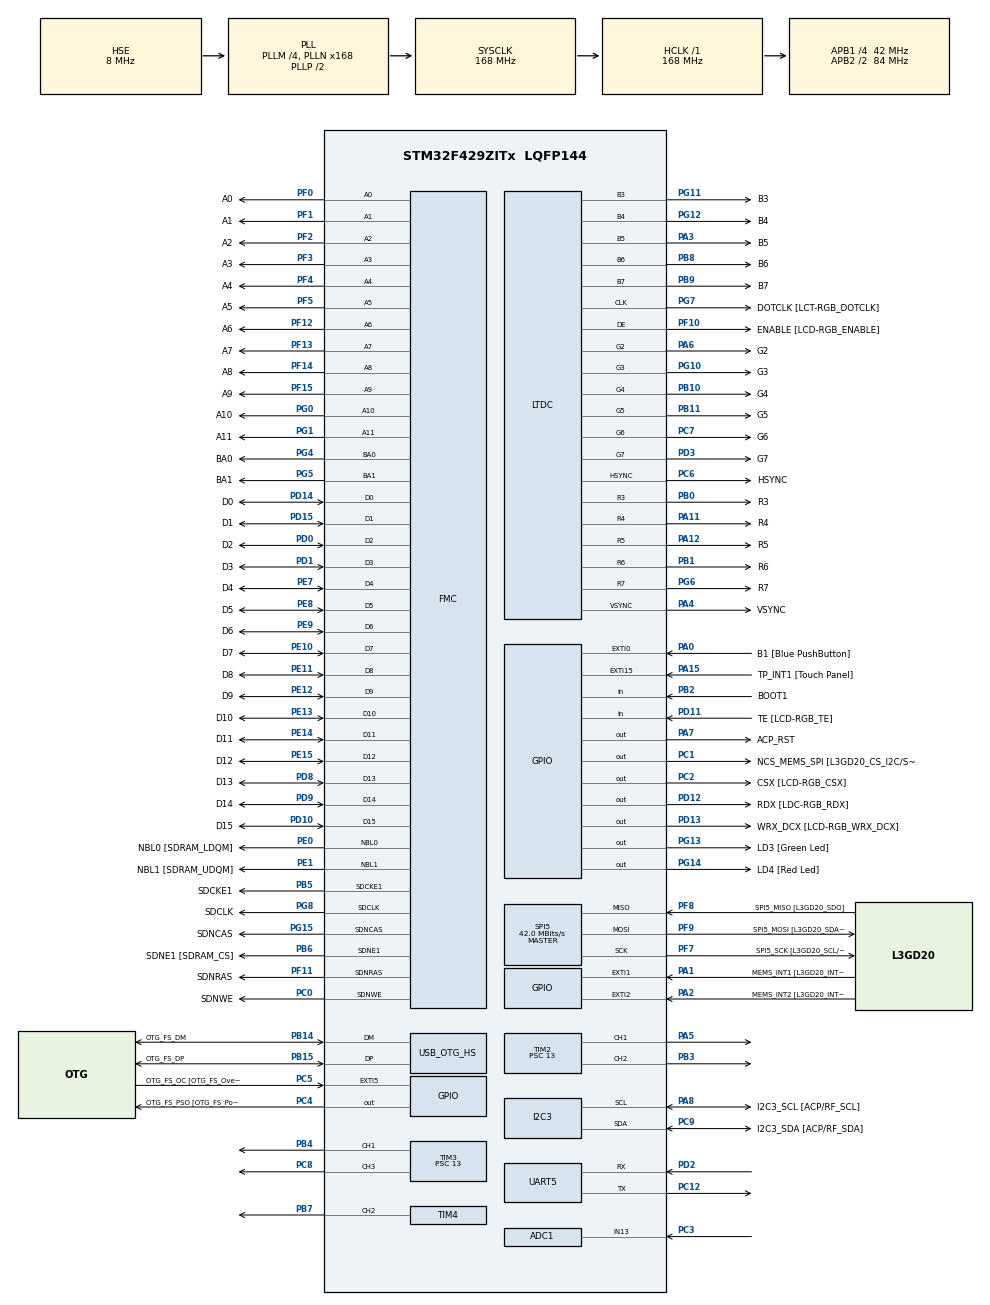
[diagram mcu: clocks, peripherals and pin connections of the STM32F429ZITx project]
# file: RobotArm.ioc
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ADC1.Channel-0\#ChannelRegularConversion=ADC_CHANNEL_13
ADC1.Channel-1\#ChannelRegularConversion=ADC_CHANNEL_TEMPSENSOR
ADC1.Channel-2\#ChannelRegularConversion=ADC_CHANNEL_VREFINT
ADC1.ClockPrescaler=ADC_CLOCK_SYNC_PCLK_DIV4
ADC1.ContinuousConvMode=ENABLE
ADC1.DMAContinuousRequests=ENABLE
ADC1.DataAlign=ADC_DATAALIGN_RIGHT
ADC1.DiscontinuousConvMode=DISABLE
ADC1.EOCSelection=ADC_EOC_SINGLE_CONV
ADC1.EnableAnalogWatchDog=false
ADC1.ExternalTrigConv=ADC_SOFTWARE_START
ADC1.ExternalTrigConvEdge=ADC_EXTERNALTRIGCONVEDGE_NONE
ADC1.InjNumberOfConversion=0
ADC1.NbrOfConversion=3
ADC1.NbrOfConversionFlag=1
ADC1.Rank-0\#ChannelRegularConversion=1
ADC1.Rank-1\#ChannelRegularConversion=2
ADC1.Rank-2\#ChannelRegularConversion=3
ADC1.Resolution=ADC_RESOLUTION_12B
ADC1.SamplingTime-0\#ChannelRegularConversion=ADC_SAMPLETIME_15CYCLES
ADC1.SamplingTime-1\#ChannelRegularConversion=ADC_SAMPLETIME_15CYCLES
ADC1.SamplingTime-2\#ChannelRegularConversion=ADC_SAMPLETIME_15CYCLES
ADC1.ScanConvMode=ENABLE
ADC1.master=1
DMA2D.AlphaModeForeground=DMA2D_NO_MODIF_ALPHA
DMA2D.ColorMode=DMA2D_OUTPUT_ARGB8888
DMA2D.InputAlphaForeground=0xFF
DMA2D.Mode=DMA2D_M2M
Dma.ADC1.0.Direction=DMA_PERIPH_TO_MEMORY
Dma.ADC1.0.FIFOMode=DMA_FIFOMODE_DISABLE
Dma.ADC1.0.Instance=DMA2_Stream4
Dma.ADC1.0.MemDataAlignment=DMA_MDATAALIGN_WORD
Dma.ADC1.0.MemInc=DMA_MINC_ENABLE
Dma.ADC1.0.Mode=DMA_CIRCULAR
Dma.ADC1.0.PeriphDataAlignment=DMA_PDATAALIGN_WORD
Dma.ADC1.0.PeriphInc=DMA_PINC_DISABLE
Dma.ADC1.0.Priority=DMA_PRIORITY_LOW
Dma.Request0=ADC1
FMC.CASLatency1=FMC_SDRAM_CAS_LATENCY_3
FMC.ExitSelfRefreshDelay1=7
FMC.LoadToActiveDelay1=2
FMC.RCDDelay1=2
FMC.RPDelay1=2
FMC.RPDelay2=2
FMC.ReadPipeDelay1=FMC_SDRAM_RPIPE_DELAY_1
FMC.ReadPipeDelay2=FMC_SDRAM_RPIPE_DELAY_1
FMC.RowCycleDelay1=7
FMC.RowCycleDelay2=7
FMC.SDClockPeriod1=FMC_SDRAM_CLOCK_PERIOD_2
FMC.SDClockPeriod2=FMC_SDRAM_CLOCK_PERIOD_2
FMC.SelfRefreshTime1=4
FMC.WriteRecoveryTime1=3
FREERTOS.Tasks01=defaultTask,-2,256,StartDefaultTask,Default,NULL,Dynamic,NULL,NULL;commTask,2,128,StartCommTask,Default,NULL,Dynamic,NULL,NULL;sensorTask,-1,128,StartSensorTask,Default,NULL,Dynamic,NULL,NULL;controlTask,1,128,StartControlTask,Default,NULL,Dynamic,NULL,NULL;servoRampTask,0,128,StartServoRampTask,Default,NULL,Dynamic,NULL,NULL;tsTask,0,128,StartTsTask,Default,NULL,Dynamic,NULL,NULL;oldGraphicsTask,-2,256,StartOldGraphicsTask,Default,NULL,Dynamic,NULL,NULL
GRAPHICS.Check_OTM8009A_PixelFormat-STemWin_F429_439=1
GRAPHICS.DMA2D_Graphics-STemWin_F429_439=1
GRAPHICS.EA_1_executable_name-STemWin_F429_439=GUIBuilder.exe
GRAPHICS.GUI_NUM_LAYERS-STemWin_F429_439=1
GRAPHICS.GUI_Num_KBYTES=110
GRAPHICS.GUI_Optimization=0
GRAPHICS.LIN_Frame_Buffer_Depth_Layer0-STemWin_F429_439=32
GRAPHICS.OPTIM_OS_use-STemWin_F429_439=6
GRAPHICS.USE_Embedded_Wizard-STemWin_F429_439=0
GRAPHICS.USE_STTouchGFX-STemWin_F429_439=0
GRAPHICS.UseGUIBuilder=Enabled
GRAPHICS.Use_SDRAM-STemWin_F429_439=SDRAM1_BANK2
GRAPHICS.Use_ili9341_Check-STemWin_F429_439=1
LTDC.ActiveH=320
LTDC.ActiveW=240
LTDC.Alpha_L0=255
LTDC.Alpha_L1=255
LTDC.BlendingFactor1_L0=LTDC_BLENDING_FACTOR1_PAxCA
LTDC.BlendingFactor1_L1=LTDC_BLENDING_FACTOR1_PAxCA
LTDC.BlendingFactor2_L0=LTDC_BLENDING_FACTOR2_PAxCA
LTDC.BlendingFactor2_L1=LTDC_BLENDING_FACTOR2_PAxCA
LTDC.FBStartAdress_L0=0xD0200000
LTDC.FBStartAdress_L1=0xD0400000
LTDC.HBP=20
LTDC.HFP=10
LTDC.HSync=10
LTDC.ImageHeight_L0=320
LTDC.ImageHeight_L1=320
LTDC.ImageWidth_L0=240
LTDC.ImageWidth_L1=240
LTDC.Layers=0
LTDC.PixelFormat_L0=LTDC_PIXEL_FORMAT_ARGB8888
LTDC.PixelFormat_L1=LTDC_PIXEL_FORMAT_ARGB8888
LTDC.VBP=2
LTDC.VFP=4
LTDC.VSync=2
LTDC.WindowX1_L0=240
LTDC.WindowX1_L1=240
LTDC.WindowY1_L0=320
LTDC.WindowY1_L1=320
Mcu.Family=STM32F4
Mcu.Name=STM32F429ZITx
Mcu.Package=LQFP144
NVIC.DMA2D_IRQn=true\:5\:0\:false\:false\:true\:true\:true
NVIC.DMA2_Stream4_IRQn=true\:0\:0\:false\:false\:true\:false\:false
NVIC.OTG_HS_IRQn=true\:5\:0\:false\:false\:true\:true\:false
NVIC.PriorityGroup=NVIC_PRIORITYGROUP_4
NVIC.TIM6_DAC_IRQn=true\:0\:0\:false\:false\:true\:false\:true
NVIC.TimeBase=TIM6_DAC_IRQn
NVIC.TimeBaseIP=TIM6
PA0/WKUP.GPIO_Label=B1 [Blue PushButton]
PA0/WKUP.GPIO_ModeDefaultEXTI=GPIO_MODE_EVT_RISING
PA0/WKUP.GPIO_PuPd=GPIO_NOPULL
PA0/WKUP.Signal=GPXTI0
PA1.GPIO_Label=MEMS_INT1 [L3GD20_INT1]
PA1.GPIO_ModeDefaultEXTI=GPIO_MODE_EVT_RISING
PA1.GPIO_PuPd=GPIO_NOPULL
PA1.Signal=GPXTI1
PA11.GPIO_Label=R4
PA11.GPIO_Mode=GPIO_MODE_AF_PP
PA11.GPIO_PuPd=GPIO_NOPULL
PA11.GPIO_Speed=GPIO_SPEED_FREQ_LOW
PA11.Mode=RGB565
PA11.Signal=LTDC_R4
PA12.GPIO_Label=R5
PA12.GPIO_Mode=GPIO_MODE_AF_PP
PA12.GPIO_PuPd=GPIO_NOPULL
PA12.GPIO_Speed=GPIO_SPEED_FREQ_LOW
PA12.Mode=RGB565
PA12.Signal=LTDC_R5
PA13.GPIO_Label=SWDIO
PA13.Signal=SYS_JTMS-SWDIO
PA14.GPIO_Label=SWCLK
PA14.Signal=SYS_JTCK-SWCLK
PA15.GPIO_Label=TP_INT1 [Touch Panel]
PA15.GPIO_ModeDefaultEXTI=GPIO_MODE_EVT_RISING
PA15.GPIO_PuPd=GPIO_NOPULL
PA15.Signal=GPXTI15
PA2.GPIO_Label=MEMS_INT2 [L3GD20_INT2]
PA2.GPIO_ModeDefaultEXTI=GPIO_MODE_EVT_RISING
PA2.GPIO_PuPd=GPIO_NOPULL
PA2.Signal=GPXTI2
PA3.GPIO_Label=B5
PA3.GPIO_Mode=GPIO_MODE_AF_PP
PA3.GPIO_PuPd=GPIO_NOPULL
PA3.GPIO_Speed=GPIO_SPEED_FREQ_LOW
PA3.Mode=RGB565
PA3.Signal=LTDC_B5
PA4.GPIO_Label=VSYNC
PA4.GPIO_Mode=GPIO_MODE_AF_PP
PA4.GPIO_PuPd=GPIO_NOPULL
PA4.GPIO_Speed=GPIO_SPEED_FREQ_LOW
PA4.Mode=RGB565
PA4.Signal=LTDC_VSYNC
PA5.Signal=S_TIM2_CH1_ETR
PA6.GPIO_Label=G2
PA6.GPIO_Mode=GPIO_MODE_AF_PP
PA6.GPIO_PuPd=GPIO_NOPULL
PA6.GPIO_Speed=GPIO_SPEED_FREQ_LOW
PA6.Mode=RGB565
PA6.Signal=LTDC_G2
PA7.GPIO_Label=ACP_RST
PA7.GPIO_Mode=GPIO_MODE_OUTPUT_PP
PA7.GPIO_PuPd=GPIO_NOPULL
PA7.GPIO_Speed=GPIO_SPEED_FREQ_LOW
PA7.Signal=GPIO_Output
PA8.GPIO_Label=I2C3_SCL [ACP/RF_SCL]
PA8.GPIO_Mode=GPIO_MODE_AF_OD
PA8.GPIO_PuPd=GPIO_NOPULL
PA8.GPIO_Speed=GPIO_SPEED_FREQ_LOW
PA8.Mode=I2C
PA8.Signal=I2C3_SCL
PB0.GPIO_Label=R3
PB0.GPIO_Mode=GPIO_MODE_AF_PP
PB0.GPIO_PuPd=GPIO_NOPULL
PB0.GPIO_Speed=GPIO_SPEED_FREQ_LOW
PB0.Mode=RGB565
PB0.Signal=LTDC_R3
PB1.GPIO_Label=R6
PB1.GPIO_Mode=GPIO_MODE_AF_PP
PB1.GPIO_PuPd=GPIO_NOPULL
PB1.GPIO_Speed=GPIO_SPEED_FREQ_LOW
PB1.Mode=RGB565
PB1.Signal=LTDC_R6
PB10.GPIO_Label=G4
PB10.GPIO_Mode=GPIO_MODE_AF_PP
PB10.GPIO_PuPd=GPIO_NOPULL
PB10.GPIO_Speed=GPIO_SPEED_FREQ_LOW
PB10.Mode=RGB565
PB10.Signal=LTDC_G4
PB11.GPIO_Label=G5
PB11.GPIO_Mode=GPIO_MODE_AF_PP
PB11.GPIO_PuPd=GPIO_NOPULL
PB11.GPIO_Speed=GPIO_SPEED_FREQ_LOW
PB11.Mode=RGB565
PB11.Signal=LTDC_G5
PB12.GPIO_Label=OTG_FS_ID
PB12.GPIO_Mode=GPIO_MODE_AF_PP
PB12.GPIO_PuPd=GPIO_NOPULL
PB12.GPIO_Speed=GPIO_SPEED_FREQ_LOW
PB12.Signal=USB_OTG_HS_ID
PB13.GPIO_Label=VBUS_FS
PB13.GPIO_Mode=GPIO_MODE_INPUT
PB13.GPIO_PuPd=GPIO_NOPULL
PB13.Signal=USB_OTG_HS_VBUS
PB14.GPIO_Label=OTG_FS_DM
PB14.GPIO_Mode=GPIO_MODE_AF_PP
PB14.GPIO_PuPd=GPIO_NOPULL
PB14.GPIO_Speed=GPIO_SPEED_FREQ_LOW
PB14.Mode=Device_Only_FS
PB14.Signal=USB_OTG_HS_DM
PB15.GPIO_Label=OTG_FS_DP
PB15.GPIO_Mode=GPIO_MODE_AF_PP
PB15.GPIO_PuPd=GPIO_NOPULL
PB15.GPIO_Speed=GPIO_SPEED_FREQ_LOW
PB15.Mode=Device_Only_FS
PB15.Signal=USB_OTG_HS_DP
PB2/BOOT1.GPIO_Label=BOOT1
PB2/BOOT1.GPIO_Mode=GPIO_MODE_INPUT
PB2/BOOT1.GPIO_PuPd=GPIO_NOPULL
PB2/BOOT1.Signal=GPIO_Input
PB3.Signal=S_TIM2_CH2
PB4.Signal=S_TIM3_CH1
PB5.GPIO_Label=SDCKE1
PB5.GPIO_Mode=GPIO_MODE_AF_PP
PB5.GPIO_PuPd=GPIO_NOPULL
PB5.GPIO_Speed=GPIO_SPEED_FREQ_VERY_HIGH
PB5.Mode=SdramChipSelect2_1
PB5.Signal=FMC_SDCKE1
PB6.GPIO_Label=SDNE1 [SDRAM_CS]
PB6.GPIO_Mode=GPIO_MODE_AF_PP
PB6.GPIO_PuPd=GPIO_NOPULL
PB6.GPIO_Speed=GPIO_SPEED_FREQ_VERY_HIGH
PB6.Mode=SdramChipSelect2_1
PB6.Signal=FMC_SDNE1
PB7.Signal=S_TIM4_CH2
PB8.GPIO_Label=B6
PB8.GPIO_Mode=GPIO_MODE_AF_PP
PB8.GPIO_PuPd=GPIO_NOPULL
PB8.GPIO_Speed=GPIO_SPEED_FREQ_LOW
PB8.Mode=RGB565
PB8.Signal=LTDC_B6
PB9.GPIO_Label=B7
PB9.GPIO_Mode=GPIO_MODE_AF_PP
PB9.GPIO_PuPd=GPIO_NOPULL
PB9.GPIO_Speed=GPIO_SPEED_FREQ_LOW
PB9.Mode=RGB565
PB9.Signal=LTDC_B7
PC0.GPIO_Label=SDNWE
PC0.GPIO_Mode=GPIO_MODE_AF_PP
PC0.GPIO_PuPd=GPIO_NOPULL
PC0.GPIO_Speed=GPIO_SPEED_FREQ_VERY_HIGH
PC0.Signal=FMC_SDNWE
PC1.GPIO_Label=NCS_MEMS_SPI [L3GD20_CS_I2C/SPI]
PC1.GPIO_Mode=GPIO_MODE_OUTPUT_PP
PC1.GPIO_PuPd=GPIO_NOPULL
PC1.GPIO_Speed=GPIO_SPEED_FREQ_LOW
PC1.Signal=GPIO_Output
PC10.GPIO_Label=R2
PC10.GPIO_Mode=GPIO_MODE_AF_PP
PC10.GPIO_PuPd=GPIO_NOPULL
PC10.GPIO_Speed=GPIO_SPEED_FREQ_LOW
PC10.Signal=LTDC_R2
PC12.Mode=Asynchronous
PC12.Signal=UART5_TX
PC14/OSC32_IN.GPIO_Label=PC14-OSC32_IN
PC14/OSC32_IN.Signal=RCC_OSC32_IN
PC15/OSC32_OUT.GPIO_Label=PC15-OSC32_OUT
PC15/OSC32_OUT.Signal=RCC_OSC32_OUT
PC2.GPIO_Label=CSX [LCD-RGB_CSX]
PC2.GPIO_Mode=GPIO_MODE_OUTPUT_PP
PC2.GPIO_PuPd=GPIO_NOPULL
PC2.GPIO_Speed=GPIO_SPEED_FREQ_LOW
PC2.Signal=GPIO_Output
PC3.Signal=ADCx_IN13
PC4.GPIO_Label=OTG_FS_PSO [OTG_FS_PowerSwitchOn]
PC4.GPIO_Mode=GPIO_MODE_OUTPUT_PP
PC4.GPIO_PuPd=GPIO_NOPULL
PC4.GPIO_Speed=GPIO_SPEED_FREQ_LOW
PC4.Signal=GPIO_Output
PC5.GPIO_Label=OTG_FS_OC [OTG_FS_OverCurrent]
PC5.GPIO_ModeDefaultEXTI=GPIO_MODE_EVT_RISING
PC5.Signal=GPXTI5
PC6.GPIO_Label=HSYNC
PC6.GPIO_Mode=GPIO_MODE_AF_PP
PC6.GPIO_PuPd=GPIO_NOPULL
PC6.GPIO_Speed=GPIO_SPEED_FREQ_LOW
PC6.Mode=RGB565
PC6.Signal=LTDC_HSYNC
PC7.GPIO_Label=G6
PC7.GPIO_Mode=GPIO_MODE_AF_PP
PC7.GPIO_PuPd=GPIO_NOPULL
PC7.GPIO_Speed=GPIO_SPEED_FREQ_LOW
PC7.Mode=RGB565
PC7.Signal=LTDC_G6
PC8.Signal=S_TIM3_CH3
PC9.GPIO_Label=I2C3_SDA [ACP/RF_SDA]
PC9.GPIO_Mode=GPIO_MODE_AF_OD
PC9.GPIO_PuPd=GPIO_NOPULL
PC9.GPIO_Speed=GPIO_SPEED_FREQ_LOW
PC9.Mode=I2C
PC9.Signal=I2C3_SDA
PD0.GPIO_Label=D2
PD0.GPIO_Mode=GPIO_MODE_AF_PP
PD0.GPIO_PuPd=GPIO_NOPULL
PD0.GPIO_Speed=GPIO_SPEED_FREQ_VERY_HIGH
PD0.Signal=FMC_D2_DA2
PD1.GPIO_Label=D3
PD1.GPIO_Mode=GPIO_MODE_AF_PP
PD1.GPIO_PuPd=GPIO_NOPULL
PD1.GPIO_Speed=GPIO_SPEED_FREQ_VERY_HIGH
PD1.Signal=FMC_D3_DA3
PD10.GPIO_Label=D15
PD10.GPIO_Mode=GPIO_MODE_AF_PP
PD10.GPIO_PuPd=GPIO_NOPULL
PD10.GPIO_Speed=GPIO_SPEED_FREQ_VERY_HIGH
PD10.Signal=FMC_D15_DA15
PD11.GPIO_Label=TE [LCD-RGB_TE]
PD11.GPIO_Mode=GPIO_MODE_INPUT
PD11.GPIO_PuPd=GPIO_NOPULL
PD11.Signal=GPIO_Input
PD12.GPIO_Label=RDX [LDC-RGB_RDX]
PD12.GPIO_Mode=GPIO_MODE_OUTPUT_PP
PD12.GPIO_PuPd=GPIO_NOPULL
PD12.GPIO_Speed=GPIO_SPEED_FREQ_LOW
PD12.Signal=GPIO_Output
PD13.GPIO_Label=WRX_DCX [LCD-RGB_WRX_DCX]
PD13.GPIO_Mode=GPIO_MODE_OUTPUT_PP
PD13.GPIO_PuPd=GPIO_NOPULL
PD13.GPIO_Speed=GPIO_SPEED_FREQ_LOW
PD13.Signal=GPIO_Output
PD14.GPIO_Label=D0
PD14.GPIO_Mode=GPIO_MODE_AF_PP
PD14.GPIO_PuPd=GPIO_NOPULL
PD14.GPIO_Speed=GPIO_SPEED_FREQ_VERY_HIGH
PD14.Signal=FMC_D0_DA0
PD15.GPIO_Label=D1
PD15.GPIO_Mode=GPIO_MODE_AF_PP
PD15.GPIO_PuPd=GPIO_NOPULL
PD15.GPIO_Speed=GPIO_SPEED_FREQ_VERY_HIGH
PD15.Signal=FMC_D1_DA1
PD2.Mode=Asynchronous
PD2.Signal=UART5_RX
PD3.GPIO_Label=G7
PD3.GPIO_Mode=GPIO_MODE_AF_PP
PD3.GPIO_PuPd=GPIO_NOPULL
PD3.GPIO_Speed=GPIO_SPEED_FREQ_LOW
PD3.Mode=RGB565
PD3.Signal=LTDC_G7
PD6.GPIO_Label=B2
PD6.GPIO_Mode=GPIO_MODE_AF_PP
PD6.GPIO_PuPd=GPIO_NOPULL
PD6.GPIO_Speed=GPIO_SPEED_FREQ_LOW
PD6.Signal=LTDC_B2
PD8.GPIO_Label=D13
PD8.GPIO_Mode=GPIO_MODE_AF_PP
PD8.GPIO_PuPd=GPIO_NOPULL
PD8.GPIO_Speed=GPIO_SPEED_FREQ_VERY_HIGH
PD8.Signal=FMC_D13_DA13
PD9.GPIO_Label=D14
PD9.GPIO_Mode=GPIO_MODE_AF_PP
PD9.GPIO_PuPd=GPIO_NOPULL
PD9.GPIO_Speed=GPIO_SPEED_FREQ_VERY_HIGH
PD9.Signal=FMC_D14_DA14
PE0.GPIO_Label=NBL0 [SDRAM_LDQM]
PE0.GPIO_Mode=GPIO_MODE_AF_PP
PE0.GPIO_PuPd=GPIO_NOPULL
PE0.GPIO_Speed=GPIO_SPEED_FREQ_VERY_HIGH
PE0.Signal=FMC_NBL0
PE1.GPIO_Label=NBL1 [SDRAM_UDQM]
PE1.GPIO_Mode=GPIO_MODE_AF_PP
PE1.GPIO_PuPd=GPIO_NOPULL
PE1.GPIO_Speed=GPIO_SPEED_FREQ_VERY_HIGH
PE1.Signal=FMC_NBL1
PE10.GPIO_Label=D7
PE10.GPIO_Mode=GPIO_MODE_AF_PP
PE10.GPIO_PuPd=GPIO_NOPULL
PE10.GPIO_Speed=GPIO_SPEED_FREQ_VERY_HIGH
PE10.Signal=FMC_D7_DA7
PE11.GPIO_Label=D8
PE11.GPIO_Mode=GPIO_MODE_AF_PP
PE11.GPIO_PuPd=GPIO_NOPULL
PE11.GPIO_Speed=GPIO_SPEED_FREQ_VERY_HIGH
PE11.Signal=FMC_D8_DA8
PE12.GPIO_Label=D9
PE12.GPIO_Mode=GPIO_MODE_AF_PP
PE12.GPIO_PuPd=GPIO_NOPULL
PE12.GPIO_Speed=GPIO_SPEED_FREQ_VERY_HIGH
PE12.Signal=FMC_D9_DA9
PE13.GPIO_Label=D10
PE13.GPIO_Mode=GPIO_MODE_AF_PP
PE13.GPIO_PuPd=GPIO_NOPULL
PE13.GPIO_Speed=GPIO_SPEED_FREQ_VERY_HIGH
PE13.Signal=FMC_D10_DA10
PE14.GPIO_Label=D11
PE14.GPIO_Mode=GPIO_MODE_AF_PP
PE14.GPIO_PuPd=GPIO_NOPULL
PE14.GPIO_Speed=GPIO_SPEED_FREQ_VERY_HIGH
PE14.Signal=FMC_D11_DA11
PE15.GPIO_Label=D12
PE15.GPIO_Mode=GPIO_MODE_AF_PP
PE15.GPIO_PuPd=GPIO_NOPULL
PE15.GPIO_Speed=GPIO_SPEED_FREQ_VERY_HIGH
PE15.Signal=FMC_D12_DA12
PE7.GPIO_Label=D4
PE7.GPIO_Mode=GPIO_MODE_AF_PP
PE7.GPIO_PuPd=GPIO_NOPULL
PE7.GPIO_Speed=GPIO_SPEED_FREQ_VERY_HIGH
PE7.Signal=FMC_D4_DA4
PE8.GPIO_Label=D5
PE8.GPIO_Mode=GPIO_MODE_AF_PP
PE8.GPIO_PuPd=GPIO_NOPULL
PE8.GPIO_Speed=GPIO_SPEED_FREQ_VERY_HIGH
PE8.Signal=FMC_D5_DA5
PE9.GPIO_Label=D6
PE9.GPIO_Mode=GPIO_MODE_AF_PP
PE9.GPIO_PuPd=GPIO_NOPULL
PE9.GPIO_Speed=GPIO_SPEED_FREQ_VERY_HIGH
PE9.Signal=FMC_D6_DA6
PF0.GPIO_Label=A0
PF0.GPIO_Mode=GPIO_MODE_AF_PP
PF0.GPIO_PuPd=GPIO_NOPULL
PF0.GPIO_Speed=GPIO_SPEED_FREQ_VERY_HIGH
PF0.Signal=FMC_A0
PF1.GPIO_Label=A1
PF1.GPIO_Mode=GPIO_MODE_AF_PP
PF1.GPIO_PuPd=GPIO_NOPULL
PF1.GPIO_Speed=GPIO_SPEED_FREQ_VERY_HIGH
PF1.Signal=FMC_A1
PF10.GPIO_Label=ENABLE [LCD-RGB_ENABLE]
PF10.GPIO_Mode=GPIO_MODE_AF_PP
PF10.GPIO_PuPd=GPIO_NOPULL
PF10.GPIO_Speed=GPIO_SPEED_FREQ_LOW
PF10.Mode=RGB565
PF10.Signal=LTDC_DE
PF11.GPIO_Label=SDNRAS
PF11.GPIO_Mode=GPIO_MODE_AF_PP
PF11.GPIO_PuPd=GPIO_NOPULL
PF11.GPIO_Speed=GPIO_SPEED_FREQ_VERY_HIGH
PF11.Signal=FMC_SDNRAS
PF12.GPIO_Label=A6
PF12.GPIO_Mode=GPIO_MODE_AF_PP
PF12.GPIO_PuPd=GPIO_NOPULL
PF12.GPIO_Speed=GPIO_SPEED_FREQ_VERY_HIGH
PF12.Signal=FMC_A6
PF13.GPIO_Label=A7
PF13.GPIO_Mode=GPIO_MODE_AF_PP
PF13.GPIO_PuPd=GPIO_NOPULL
PF13.GPIO_Speed=GPIO_SPEED_FREQ_VERY_HIGH
PF13.Signal=FMC_A7
PF14.GPIO_Label=A8
PF14.GPIO_Mode=GPIO_MODE_AF_PP
PF14.GPIO_PuPd=GPIO_NOPULL
PF14.GPIO_Speed=GPIO_SPEED_FREQ_VERY_HIGH
PF14.Signal=FMC_A8
PF15.GPIO_Label=A9
PF15.GPIO_Mode=GPIO_MODE_AF_PP
PF15.GPIO_PuPd=GPIO_NOPULL
PF15.GPIO_Speed=GPIO_SPEED_FREQ_VERY_HIGH
PF15.Signal=FMC_A9
PF2.GPIO_Label=A2
PF2.GPIO_Mode=GPIO_MODE_AF_PP
PF2.GPIO_PuPd=GPIO_NOPULL
PF2.GPIO_Speed=GPIO_SPEED_FREQ_VERY_HIGH
PF2.Signal=FMC_A2
PF3.GPIO_Label=A3
PF3.GPIO_Mode=GPIO_MODE_AF_PP
PF3.GPIO_PuPd=GPIO_NOPULL
PF3.GPIO_Speed=GPIO_SPEED_FREQ_VERY_HIGH
PF3.Signal=FMC_A3
PF4.GPIO_Label=A4
PF4.GPIO_Mode=GPIO_MODE_AF_PP
PF4.GPIO_PuPd=GPIO_NOPULL
PF4.GPIO_Speed=GPIO_SPEED_FREQ_VERY_HIGH
PF4.Signal=FMC_A4
PF5.GPIO_Label=A5
PF5.GPIO_Mode=GPIO_MODE_AF_PP
PF5.GPIO_PuPd=GPIO_NOPULL
PF5.GPIO_Speed=GPIO_SPEED_FREQ_VERY_HIGH
PF5.Signal=FMC_A5
PF7.GPIO_Label=SPI5_SCK [L3GD20_SCL/SPC]
PF7.GPIO_Mode=GPIO_MODE_AF_PP
PF7.GPIO_PuPd=GPIO_NOPULL
PF7.GPIO_Speed=GPIO_SPEED_FREQ_LOW
PF7.Mode=Full_Duplex_Master
PF7.Signal=SPI5_SCK
PF8.GPIO_Label=SPI5_MISO [L3GD20_SDO]
PF8.GPIO_Mode=GPIO_MODE_AF_PP
PF8.GPIO_PuPd=GPIO_NOPULL
PF8.GPIO_Speed=GPIO_SPEED_FREQ_LOW
PF8.Mode=Full_Duplex_Master
PF8.Signal=SPI5_MISO
PF9.GPIO_Label=SPI5_MOSI [L3GD20_SDA/SDI/SDO]
PF9.GPIO_Mode=GPIO_MODE_AF_PP
PF9.GPIO_PuPd=GPIO_NOPULL
PF9.GPIO_Speed=GPIO_SPEED_FREQ_LOW
PF9.Mode=Full_Duplex_Master
PF9.Signal=SPI5_MOSI
PG0.GPIO_Label=A10
PG0.GPIO_Mode=GPIO_MODE_AF_PP
PG0.GPIO_PuPd=GPIO_NOPULL
PG0.GPIO_Speed=GPIO_SPEED_FREQ_VERY_HIGH
PG0.Signal=FMC_A10
PG1.GPIO_Label=A11
PG1.GPIO_Mode=GPIO_MODE_AF_PP
PG1.GPIO_PuPd=GPIO_NOPULL
PG1.GPIO_Speed=GPIO_SPEED_FREQ_VERY_HIGH
PG1.Signal=FMC_A11
PG10.GPIO_Label=G3
PG10.GPIO_Mode=GPIO_MODE_AF_PP
PG10.GPIO_PuPd=GPIO_NOPULL
PG10.GPIO_Speed=GPIO_SPEED_FREQ_LOW
PG10.Mode=RGB565
PG10.Signal=LTDC_G3
PG11.GPIO_Label=B3
PG11.GPIO_Mode=GPIO_MODE_AF_PP
PG11.GPIO_PuPd=GPIO_NOPULL
PG11.GPIO_Speed=GPIO_SPEED_FREQ_LOW
PG11.Mode=RGB565
PG11.Signal=LTDC_B3
PG12.GPIO_Label=B4
PG12.GPIO_Mode=GPIO_MODE_AF_PP
PG12.GPIO_PuPd=GPIO_NOPULL
PG12.GPIO_Speed=GPIO_SPEED_FREQ_LOW
PG12.Mode=RGB565
PG12.Signal=LTDC_B4
PG13.GPIO_Label=LD3 [Green Led]
PG13.GPIO_Mode=GPIO_MODE_OUTPUT_PP
PG13.GPIO_PuPd=GPIO_NOPULL
PG13.GPIO_Speed=GPIO_SPEED_FREQ_LOW
PG13.Signal=GPIO_Output
PG14.GPIO_Label=LD4 [Red Led]
PG14.GPIO_Mode=GPIO_MODE_OUTPUT_PP
PG14.GPIO_PuPd=GPIO_NOPULL
PG14.GPIO_Speed=GPIO_SPEED_FREQ_LOW
PG14.Signal=GPIO_Output
PG15.GPIO_Label=SDNCAS
PG15.GPIO_Mode=GPIO_MODE_AF_PP
PG15.GPIO_PuPd=GPIO_NOPULL
PG15.GPIO_Speed=GPIO_SPEED_FREQ_VERY_HIGH
PG15.Signal=FMC_SDNCAS
PG4.GPIO_Label=BA0
PG4.GPIO_Mode=GPIO_MODE_AF_PP
PG4.GPIO_PuPd=GPIO_NOPULL
PG4.GPIO_Speed=GPIO_SPEED_FREQ_VERY_HIGH
PG4.Signal=FMC_A14_BA0
PG5.GPIO_Label=BA1
PG5.GPIO_Mode=GPIO_MODE_AF_PP
PG5.GPIO_PuPd=GPIO_NOPULL
PG5.GPIO_Speed=GPIO_SPEED_FREQ_VERY_HIGH
PG5.Signal=FMC_A15_BA1
PG6.GPIO_Label=R7
PG6.GPIO_Mode=GPIO_MODE_AF_PP
PG6.GPIO_PuPd=GPIO_NOPULL
PG6.GPIO_Speed=GPIO_SPEED_FREQ_LOW
PG6.Mode=RGB565
PG6.Signal=LTDC_R7
PG7.GPIO_Label=DOTCLK [LCT-RGB_DOTCLK]
PG7.GPIO_Mode=GPIO_MODE_AF_PP
PG7.GPIO_PuPd=GPIO_NOPULL
PG7.GPIO_Speed=GPIO_SPEED_FREQ_LOW
PG7.Mode=RGB565
PG7.Signal=LTDC_CLK
PG8.GPIO_Label=SDCLK
PG8.GPIO_Mode=GPIO_MODE_AF_PP
PG8.GPIO_PuPd=GPIO_NOPULL
PG8.GPIO_Speed=GPIO_SPEED_FREQ_VERY_HIGH
PG8.Signal=FMC_SDCLK
PH0/OSC_IN.GPIO_Label=PH0-OSC_IN
PH0/OSC_IN.Mode=HSE-External-Oscillator
PH0/OSC_IN.Signal=RCC_OSC_IN
PH1/OSC_OUT.GPIO_Label=PH1-OSC_OUT
PH1/OSC_OUT.Mode=HSE-External-Oscillator
PH1/OSC_OUT.Signal=RCC_OSC_OUT
ProjectManager.HeapSize=0x1000
ProjectManager.StackSize=0x600
ProjectManager.TargetToolchain=EWARM
RCC.48MHZClocksFreq_Value=48000000
RCC.AHBFreq_Value=168000000
RCC.APB1CLKDivider=RCC_HCLK_DIV4
RCC.APB1Freq_Value=42000000
RCC.APB1TimFreq_Value=84000000
RCC.APB2CLKDivider=RCC_HCLK_DIV2
RCC.APB2Freq_Value=84000000
RCC.APB2TimFreq_Value=168000000
RCC.CortexFreq_Value=168000000
RCC.HCLKFreq_Value=168000000
RCC.HSE_VALUE=8000000
RCC.HSI_VALUE=16000000
RCC.LSE_VALUE=32768
RCC.PLLM=4
RCC.PLLN=168
RCC.PLLQ=7
RCC.PLLSAIDivR=RCC_PLLSAIDIVR_4
RCC.PLLSAIN=84
RCC.PLLSAIR=7
RCC.SYSCLKFreq_VALUE=168000000
RCC.SYSCLKSource=RCC_SYSCLKSOURCE_PLLCLK
RCC.VCOOutputFreq_Value=336000000
SH.ADCx_IN13.0=ADC1_IN13,IN13
SH.FMC_A0.0=FMC_A0,12b-sda1
SH.FMC_A1.0=FMC_A1,12b-sda1
SH.FMC_A10.0=FMC_A10,12b-sda1
SH.FMC_A11.0=FMC_A11,12b-sda1
SH.FMC_A14_BA0.0=FMC_BA0,FourSdramBanks1
SH.FMC_A15_BA1.0=FMC_BA1,FourSdramBanks1
SH.FMC_A2.0=FMC_A2,12b-sda1
SH.FMC_A3.0=FMC_A3,12b-sda1
SH.FMC_A4.0=FMC_A4,12b-sda1
SH.FMC_A5.0=FMC_A5,12b-sda1
SH.FMC_A6.0=FMC_A6,12b-sda1
SH.FMC_A7.0=FMC_A7,12b-sda1
SH.FMC_A8.0=FMC_A8,12b-sda1
SH.FMC_A9.0=FMC_A9,12b-sda1
SH.FMC_D0_DA0.0=FMC_D0,sd-16b-d1
SH.FMC_D10_DA10.0=FMC_D10,sd-16b-d1
SH.FMC_D11_DA11.0=FMC_D11,sd-16b-d1
SH.FMC_D12_DA12.0=FMC_D12,sd-16b-d1
SH.FMC_D13_DA13.0=FMC_D13,sd-16b-d1
SH.FMC_D14_DA14.0=FMC_D14,sd-16b-d1
SH.FMC_D15_DA15.0=FMC_D15,sd-16b-d1
SH.FMC_D1_DA1.0=FMC_D1,sd-16b-d1
SH.FMC_D2_DA2.0=FMC_D2,sd-16b-d1
SH.FMC_D3_DA3.0=FMC_D3,sd-16b-d1
SH.FMC_D4_DA4.0=FMC_D4,sd-16b-d1
SH.FMC_D5_DA5.0=FMC_D5,sd-16b-d1
SH.FMC_D6_DA6.0=FMC_D6,sd-16b-d1
SH.FMC_D7_DA7.0=FMC_D7,sd-16b-d1
SH.FMC_D8_DA8.0=FMC_D8,sd-16b-d1
SH.FMC_D9_DA9.0=FMC_D9,sd-16b-d1
SH.FMC_NBL0.0=FMC_NBL0,Sd2ByteEnable1
SH.FMC_NBL1.0=FMC_NBL1,Sd2ByteEnable1
SH.FMC_SDCLK.0=FMC_SDCLK,12b-sda1
SH.FMC_SDNCAS.0=FMC_SDNCAS,12b-sda1
SH.FMC_SDNRAS.0=FMC_SDNRAS,12b-sda1
SH.FMC_SDNWE.0=FMC_SDNWE,12b-sda1
SH.S_TIM2_CH1_ETR.0=TIM2_CH1,PWM Generation1 CH1
SH.S_TIM2_CH2.0=TIM2_CH2,PWM Generation2 CH2
SH.S_TIM3_CH1.0=TIM3_CH1,PWM Generation1 CH1
SH.S_TIM3_CH3.0=TIM3_CH3,PWM Generation3 CH3
SH.S_TIM4_CH2.0=TIM4_CH2,PWM Generation2 CH2
SPI5.BaudRatePrescaler=SPI_BAUDRATEPRESCALER_2
SPI5.CalculateBaudRate=42.0 MBits/s
SPI5.Direction=SPI_DIRECTION_2LINES
SPI5.Mode=SPI_MODE_MASTER
SPI5.VirtualType=VM_MASTER
TIM2.Channel-PWM\ Generation1\ CH1=TIM_CHANNEL_1
TIM2.Channel-PWM\ Generation2\ CH2=TIM_CHANNEL_2
TIM2.Period=60000
TIM2.Prescaler=13
TIM3.Channel-PWM\ Generation1\ CH1=TIM_CHANNEL_1
TIM3.Channel-PWM\ Generation3\ CH3=TIM_CHANNEL_3
TIM3.Period=60000
TIM3.Prescaler=13
TIM4.Channel-PWM\ Generation2\ CH2=TIM_CHANNEL_2
TIM4.Period=60000
TIM4.Prescaler=13
UART5.VirtualMode=Asynchronous
USB_DEVICE.CLASS_NAME_HS=CDC
USB_DEVICE.VirtualMode-CDC_HS=Cdc
USB_DEVICE.VirtualModeHS=Cdc_HS
USB_OTG_HS.VirtualMode-Device_Only_FS=Device_Only_FS
VP_ADC1_TempSens_Input.Mode=IN-TempSens
VP_ADC1_Vref_Input.Mode=IN-Vrefint
VP_CRC_VS_CRC.Mode=CRC_Activate
VP_DMA2D_VS_DMA2D.Mode=DMA2D_Activate
VP_FREERTOS_VS_ENABLE.Mode=Enabled
VP_GRAPHICS_VS-DisplayInterface-LTDC.Mode=Display Parallel Interface using LTDC
VP_GRAPHICS_VS-STemWin.Mode=STemWin_F429_439
VP_RNG_VS_RNG.Mode=RNG_Activate
VP_SYS_VS_tim6.Mode=TIM6
VP_USB_DEVICE_VS_USB_DEVICE_CDC_HS.Mode=CDC_HS
board=STM32F429I-DISCO

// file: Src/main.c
/**
  ******************************************************************************
  * @file           : main.c
  * @brief          : Main program body
  ******************************************************************************
  * This notice applies to any and all portions of this file
  * that are not between comment pairs USER CODE BEGIN and
  * USER CODE END. Other portions of this file, whether
  * inserted by the user or by software development tools
  * are owned by their respective copyright owners.
  *
  * Copyright (c) 2018 STMicroelectronics International N.V.
  * All rights reserved.
  *
  * Redistribution and use in source and binary forms, with or without
  * modification, are permitted, provided that the following conditions are met:
  *
  * 1. Redistribution of source code must retain the above copyright notice,
  *    this list of conditions and the following disclaimer.
  * 2. Redistributions in binary form must reproduce the above copyright notice,
  *    this list of conditions and the following disclaimer in the documentation
  *    and/or other materials provided with the distribution.
  * 3. Neither the name of STMicroelectronics nor the names of other
  *    contributors to this software may be used to endorse or promote products
  *    derived from this software without specific written permission.
  * 4. This software, including modifications and/or derivative works of this
  *    software, must execute solely and exclusively on microcontroller or
  *    microprocessor devices manufactured by or for STMicroelectronics.
  * 5. Redistribution and use of this software other than as permitted under
  *    this license is void and will automatically terminate your rights under
  *    this license.
  *
  * THIS SOFTWARE IS PROVIDED BY STMICROELECTRONICS AND CONTRIBUTORS "AS IS"
  * AND ANY EXPRESS, IMPLIED OR STATUTORY WARRANTIES, INCLUDING, BUT NOT
  * LIMITED TO, THE IMPLIED WARRANTIES OF MERCHANTABILITY, FITNESS FOR A
  * PARTICULAR PURPOSE AND NON-INFRINGEMENT OF THIRD PARTY INTELLECTUAL PROPERTY
  * RIGHTS ARE DISCLAIMED TO THE FULLEST EXTENT PERMITTED BY LAW. IN NO EVENT
  * SHALL STMICROELECTRONICS OR CONTRIBUTORS BE LIABLE FOR ANY DIRECT, INDIRECT,
  * INCIDENTAL, SPECIAL, EXEMPLARY, OR CONSEQUENTIAL DAMAGES (INCLUDING, BUT NOT
  * LIMITED TO, PROCUREMENT OF SUBSTITUTE GOODS OR SERVICES; LOSS OF USE, DATA,
  * OR PROFITS; OR BUSINESS INTERRUPTION) HOWEVER CAUSED AND ON ANY THEORY OF
  * LIABILITY, WHETHER IN CONTRACT, STRICT LIABILITY, OR TORT (INCLUDING
  * NEGLIGENCE OR OTHERWISE) ARISING IN ANY WAY OUT OF THE USE OF THIS SOFTWARE,
  * EVEN IF ADVISED OF THE POSSIBILITY OF SUCH DAMAGE.
  *
  ******************************************************************************
  */
#include "main.h"
#include "stm32f4xx_hal.h"
#include "cmsis_os.h"
#include "usb_device.h"

/* USER CODE BEGIN Includes */
#include "../BSP/stm32f429i_discovery.h"
#include "../BSP/stm32f429i_discovery_lcd.h"
#include "../BSP/stm32f429i_discovery_ts.h"
#include <math.h>
/* USER CODE END Includes */

ADC_HandleTypeDef hadc1;
DMA_HandleTypeDef hdma_adc1;

CRC_HandleTypeDef hcrc;

I2C_HandleTypeDef hi2c3;

RNG_HandleTypeDef hrng;

SPI_HandleTypeDef hspi5;

TIM_HandleTypeDef htim2;
TIM_HandleTypeDef htim3;
TIM_HandleTypeDef htim4;

UART_HandleTypeDef huart5;

osThreadId defaultTaskHandle;
osThreadId commTaskHandle;
osThreadId sensorTaskHandle;
osThreadId controlTaskHandle;
osThreadId servoRampTaskHandle;
osThreadId tsTaskHandle;
osThreadId oldGraphicsTaskHandle;

/* USER CODE BEGIN PV */
/* Private variables ---------------------------------------------------------*/
//#define LCD_FRAME_BUFFER_LAYER0                  (LCD_FRAME_BUFFER+0x130000)
//#define LCD_FRAME_BUFFER_LAYER1                  LCD_FRAME_BUFFER
#define F32_PI 3.1415927
#define BACKGROUND_COLOR LCD_COLOR_BLACK
typedef struct
{
  float X;
  float Y;
} XYCoordinates;

typedef struct
{
  float X;
  float Y;
  float Z;
} XYZCoordinates;

typedef struct
{
  float joint1Angle;
  float joint2angle;
} JointAngles;

typedef struct
{
  float jointXAngle;
  float jointYAngle;
  float jointZAngle;
} JointAngles3Axis;

static volatile float horLinkLength = 0.15;
static volatile float verLinkLength = 0.135;

static volatile float horLinkAngle = 45;
static volatile float verLinkAngle = 45;
static volatile float turnAngle = 0;

static volatile float dutyCycle2DegFactor = 17.0;

#define servo1calib 0.7
#define servo4calib -0.85

static volatile float servo1NewPosRef = 7.5 + servo1calib; // forgato 8.2 a valodi kozep
static volatile float servo2NewPosRef = 8.8;  // vizszintes
static volatile float servo3NewPosRef = 3.9;   // fuggoleges
static volatile float servo4NewPosRef = 7.5 + servo4calib; // megfogo 11.25
static volatile float servo5NewPosRef = 7.5;

static volatile float servo1NewPos = 7.5;
static volatile float servo2NewPos = 10;
static volatile float servo3NewPos = 3.7;
static volatile float servo4NewPos = 7.5;
static volatile float servo5NewPos = 7.5;

static volatile float servo1CurrPos = 7.5;
static volatile float servo2CurrPos = 8.8;
static volatile float servo3CurrPos = 3.9;
static volatile float servo4CurrPos = 7.5; //11.25
static volatile float servo5CurrPos = 7.5;

static volatile float servo1Min = 2.5;
static volatile float servo2Min = 6.5;
static volatile float servo3Min = 3.7;
static volatile float servo4Min = 2.5;
static volatile float servo5Min = 5;

static volatile float servo1Max = 12.5;
static volatile float servo2Max = 11.5;
static volatile float servo3Max = 8.3;
static volatile float servo4Max = 12.5;//11.3
static volatile float servo5Max = 10;

static volatile float servo1StepSize = 0.014;
static volatile float servo2StepSize = 0.024;
static volatile float servo3StepSize = 0.024;
static volatile float servo4StepSize = 0.024;
static volatile float servo5StepSize = 0.024;

static volatile int mode = 0;
static volatile int cycleRepeat = 0;
static volatile int graphicsEna =1;

char txBuf[30];
char rxBuf[64];
uint8_t receiveState = 0;

Point verLinkPoints[4];
Point horLinkPoints[4];

XYCoordinates coordinates;
XYZCoordinates coordinatesXYZ;
JointAngles calculatedAngles;
JointAngles3Axis calculatedAngles3Axis;

static volatile uint32_t ADC_Buf[3];
static volatile uint32_t val[3];
static volatile float pressLength = 0;

static volatile int PenControlActive = 0;

static volatile float targetStepSizeVar = 0.04;//0.024; // 1 deg/s = 0.00588
static volatile float numberOfSteps = 0;

static uint32_t TSx = 0, TSy = 0;

static volatile float pressThreshold = 0.5;
static volatile float pressTarget = 1.8;

static volatile uint32_t taskCounterDefaultTask     = 0;
static volatile uint32_t taskCounterCommTask        = 0;
static volatile uint32_t taskCounterSensorTask      = 0;
static volatile uint32_t taskCounterControlTask     = 0;
static volatile uint32_t taskCounterServoRampTask   = 0;
static volatile uint32_t taskCounterTsTask          = 0;
static volatile uint32_t taskCounterOldGraphicsTask = 0;
/* USER CODE END PV */

void SystemClock_Config(void);
static void MX_GPIO_Init(void);
static void MX_DMA_Init(void);
static void MX_TIM2_Init(void);
static void MX_TIM3_Init(void);
static void MX_TIM4_Init(void);
static void MX_UART5_Init(void);
static void MX_SPI5_Init(void);
static void MX_I2C3_Init(void);
static void MX_RNG_Init(void);
static void MX_ADC1_Init(void);
static void MX_CRC_Init(void);
extern void GRAPHICS_HW_Init(void);
extern void GRAPHICS_Init(void);
extern void GRAPHICS_MainTask(void);
void StartDefaultTask(void const * argument);
void StartCommTask(void const * argument);
void StartSensorTask(void const * argument);
void StartControlTask(void const * argument);
void StartServoRampTask(void const * argument);
void StartTsTask(void const * argument);
void StartOldGraphicsTask(void const * argument);

void HAL_TIM_MspPostInit(TIM_HandleTypeDef *htim);

/* USER CODE BEGIN PFP */
/* Private function prototypes -----------------------------------------------*/
extern uint8_t CDC_Transmit_HS(uint8_t* Buf, uint16_t Len);
/* USER CODE END PFP */

/* USER CODE BEGIN 0 */
void HAL_ADC_ConvCpltCallback(ADC_HandleTypeDef* hadc){

  if(hadc->Instance==ADC1){
    val[0] = ADC_Buf[0];
    val[1] = ADC_Buf[1];
    val[2] = ADC_Buf[2];
  }
}
/* USER CODE END 0 */

int main(void)
{

  /* MCU Configuration----------------------------------------------------------*/

  /* Reset of all peripherals, Initializes the Flash interface and the Systick. */
  HAL_Init();

  /* Configure the system clock */
  SystemClock_Config();

  /* Initialize all configured peripherals */
  MX_GPIO_Init();
  MX_DMA_Init();
  MX_TIM2_Init();
  MX_TIM3_Init();
  MX_TIM4_Init();
  MX_UART5_Init();
  MX_SPI5_Init();
  MX_I2C3_Init();
  MX_RNG_Init();
  MX_ADC1_Init();
  MX_CRC_Init();
  /* USER CODE BEGIN 2 */
  HAL_TIM_PWM_Start(&htim2, TIM_CHANNEL_1);    //servoPWM1
  HAL_TIMEx_PWMN_Start(&htim2, TIM_CHANNEL_1);
  HAL_TIM_PWM_Start(&htim2, TIM_CHANNEL_2);    //servoPWM2
  HAL_TIMEx_PWMN_Start(&htim2, TIM_CHANNEL_2);
  HAL_TIM_PWM_Start(&htim3, TIM_CHANNEL_1);    //servoPWM3
  HAL_TIMEx_PWMN_Start(&htim3, TIM_CHANNEL_1);
  HAL_TIM_PWM_Start(&htim3, TIM_CHANNEL_3);    //servoPWM4
  HAL_TIMEx_PWMN_Start(&htim3, TIM_CHANNEL_3);
  HAL_TIM_PWM_Start(&htim4, TIM_CHANNEL_2);    //servoPWM5
  HAL_TIMEx_PWMN_Start(&htim4, TIM_CHANNEL_2);

  //TIM2->CCR1 = (int)(7.5*45000/100);//7.5 = 1.5ms
  //TIM2->CCR2 = (int)(7.5*45000/100);//10 = 2ms
  //TIM3->CCR1 = (int)(6.3*45000/100);//5 = 1ms
  //TIM3->CCR3 = (int)(7.5*45000/100);
  //TIM4->CCR2 = (int)(7.5*45000/100);

  //min 2.5 max 12.5                   -->
  //2: 2.12 a max 1.2ms a min         -->      10.5...6.5
  //3: 1.65 ms max, 1.3ms a min  --> %-ban 8...6.3

  BSP_LED_On(LED3);
  BSP_LED_On(LED4);

  /* Configure USER Button */
  BSP_PB_Init(BUTTON_KEY, BUTTON_MODE_EXTI);

  /*##-1- LCD Initialization #################################################*/
  /* Initialize the LCD */
  /*
  BSP_LCD_Init();
  BSP_LCD_LayerDefaultInit(0, LCD_FRAME_BUFFER_LAYER0);
  */

  //BSP_LCD_SetFont(&Font24);
  //Touchscreen_Calibration();
  BSP_TS_Init(BSP_LCD_GetXSize(), BSP_LCD_GetYSize());

  /* USER CODE END 2 */

/* Initialise the graphical hardware */
  GRAPHICS_HW_Init();

  /* Initialise the graphical stack engine */
  GRAPHICS_Init();

  /* Create the thread(s) */
  /* definition and creation of defaultTask */
  osThreadDef(defaultTask, StartDefaultTask, osPriorityLow, 0, 256);
  defaultTaskHandle = osThreadCreate(osThread(defaultTask), NULL);

  /* definition and creation of commTask */
  osThreadDef(commTask, StartCommTask, osPriorityHigh, 0, 128);
  commTaskHandle = osThreadCreate(osThread(commTask), NULL);

  /* definition and creation of sensorTask */
  osThreadDef(sensorTask, StartSensorTask, osPriorityBelowNormal, 0, 128);
  sensorTaskHandle = osThreadCreate(osThread(sensorTask), NULL);

  /* definition and creation of controlTask */
  osThreadDef(controlTask, StartControlTask, osPriorityAboveNormal, 0, 128);
  controlTaskHandle = osThreadCreate(osThread(controlTask), NULL);

  /* definition and creation of servoRampTask */
  osThreadDef(servoRampTask, StartServoRampTask, osPriorityNormal, 0, 128);
  servoRampTaskHandle = osThreadCreate(osThread(servoRampTask), NULL);

  /* definition and creation of tsTask */
  osThreadDef(tsTask, StartTsTask, osPriorityNormal, 0, 128);
  tsTaskHandle = osThreadCreate(osThread(tsTask), NULL);

  /* definition and creation of oldGraphicsTask */
  osThreadDef(oldGraphicsTask, StartOldGraphicsTask, osPriorityLow, 0, 256);
  oldGraphicsTaskHandle = osThreadCreate(osThread(oldGraphicsTask), NULL);

  /* Start scheduler */
  osKernelStart();

  /* We should never get here as control is now taken by the scheduler */

  /* Infinite loop */
  while (1)
  {

  }

}

void SystemClock_Config(void)
{

  RCC_OscInitTypeDef RCC_OscInitStruct;
  RCC_ClkInitTypeDef RCC_ClkInitStruct;
  RCC_PeriphCLKInitTypeDef PeriphClkInitStruct;

    /**Configure the main internal regulator output voltage
    */
  __HAL_RCC_PWR_CLK_ENABLE();

  __HAL_PWR_VOLTAGESCALING_CONFIG(PWR_REGULATOR_VOLTAGE_SCALE1);

    /**Initializes the CPU, AHB and APB busses clocks
    */
  RCC_OscInitStruct.OscillatorType = RCC_OSCILLATORTYPE_HSE;
  RCC_OscInitStruct.HSEState = RCC_HSE_ON;
  RCC_OscInitStruct.PLL.PLLState = RCC_PLL_ON;
  RCC_OscInitStruct.PLL.PLLSource = RCC_PLLSOURCE_HSE;
  RCC_OscInitStruct.PLL.PLLM = 4;
  RCC_OscInitStruct.PLL.PLLN = 168;
  RCC_OscInitStruct.PLL.PLLP = RCC_PLLP_DIV2;
  RCC_OscInitStruct.PLL.PLLQ = 7;
  if (HAL_RCC_OscConfig(&RCC_OscInitStruct) != HAL_OK)
  {
    _Error_Handler(__FILE__, __LINE__);
  }

    /**Initializes the CPU, AHB and APB busses clocks
    */
  RCC_ClkInitStruct.ClockType = RCC_CLOCKTYPE_HCLK|RCC_CLOCKTYPE_SYSCLK
                              |RCC_CLOCKTYPE_PCLK1|RCC_CLOCKTYPE_PCLK2;
  RCC_ClkInitStruct.SYSCLKSource = RCC_SYSCLKSOURCE_PLLCLK;
  RCC_ClkInitStruct.AHBCLKDivider = RCC_SYSCLK_DIV1;
  RCC_ClkInitStruct.APB1CLKDivider = RCC_HCLK_DIV4;
  RCC_ClkInitStruct.APB2CLKDivider = RCC_HCLK_DIV2;

  if (HAL_RCC_ClockConfig(&RCC_ClkInitStruct, FLASH_LATENCY_5) != HAL_OK)
  {
    _Error_Handler(__FILE__, __LINE__);
  }

  PeriphClkInitStruct.PeriphClockSelection = RCC_PERIPHCLK_LTDC;
  PeriphClkInitStruct.PLLSAI.PLLSAIN = 84;
  PeriphClkInitStruct.PLLSAI.PLLSAIR = 7;
  PeriphClkInitStruct.PLLSAIDivR = RCC_PLLSAIDIVR_4;
  if (HAL_RCCEx_PeriphCLKConfig(&PeriphClkInitStruct) != HAL_OK)
  {
    _Error_Handler(__FILE__, __LINE__);
  }

    /**Configure the Systick interrupt time
    */
  HAL_SYSTICK_Config(HAL_RCC_GetHCLKFreq()/1000);

    /**Configure the Systick
    */
  HAL_SYSTICK_CLKSourceConfig(SYSTICK_CLKSOURCE_HCLK);

  /* SysTick_IRQn interrupt configuration */
  HAL_NVIC_SetPriority(SysTick_IRQn, 15, 0);
}

/* ADC1 init function */
static void MX_ADC1_Init(void)
{

  ADC_ChannelConfTypeDef sConfig;

    /**Configure the global features of the ADC (Clock, Resolution, Data Alignment and number of conversion)
    */
  hadc1.Instance = ADC1;
  hadc1.Init.ClockPrescaler = ADC_CLOCK_SYNC_PCLK_DIV4;
  hadc1.Init.Resolution = ADC_RESOLUTION_12B;
  hadc1.Init.ScanConvMode = ENABLE;
  hadc1.Init.ContinuousConvMode = ENABLE;
  hadc1.Init.DiscontinuousConvMode = DISABLE;
  hadc1.Init.ExternalTrigConvEdge = ADC_EXTERNALTRIGCONVEDGE_NONE;
  hadc1.Init.ExternalTrigConv = ADC_SOFTWARE_START;
  hadc1.Init.DataAlign = ADC_DATAALIGN_RIGHT;
  hadc1.Init.NbrOfConversion = 3;
  hadc1.Init.DMAContinuousRequests = ENABLE;
  hadc1.Init.EOCSelection = ADC_EOC_SINGLE_CONV;
  if (HAL_ADC_Init(&hadc1) != HAL_OK)
  {
    _Error_Handler(__FILE__, __LINE__);
  }

    /**Configure for the selected ADC regular channel its corresponding rank in the sequencer and its sample time.
    */
  sConfig.Channel = ADC_CHANNEL_13;
  sConfig.Rank = 1;
  sConfig.SamplingTime = ADC_SAMPLETIME_15CYCLES;
  if (HAL_ADC_ConfigChannel(&hadc1, &sConfig) != HAL_OK)
  {
    _Error_Handler(__FILE__, __LINE__);
  }

    /**Configure for the selected ADC regular channel its corresponding rank in the sequencer and its sample time.
    */
  sConfig.Channel = ADC_CHANNEL_TEMPSENSOR;
  sConfig.Rank = 2;
  if (HAL_ADC_ConfigChannel(&hadc1, &sConfig) != HAL_OK)
  {
    _Error_Handler(__FILE__, __LINE__);
  }

    /**Configure for the selected ADC regular channel its corresponding rank in the sequencer and its sample time.
    */
  sConfig.Channel = ADC_CHANNEL_VREFINT;
  sConfig.Rank = 3;
  if (HAL_ADC_ConfigChannel(&hadc1, &sConfig) != HAL_OK)
  {
    _Error_Handler(__FILE__, __LINE__);
  }

}

/* CRC init function */
static void MX_CRC_Init(void)
{

  hcrc.Instance = CRC;
  if (HAL_CRC_Init(&hcrc) != HAL_OK)
  {
    _Error_Handler(__FILE__, __LINE__);
  }

}

/* I2C3 init function */
static void MX_I2C3_Init(void)
{

  hi2c3.Instance = I2C3;
  hi2c3.Init.ClockSpeed = 100000;
  hi2c3.Init.DutyCycle = I2C_DUTYCYCLE_2;
  hi2c3.Init.OwnAddress1 = 0;
  hi2c3.Init.AddressingMode = I2C_ADDRESSINGMODE_7BIT;
  hi2c3.Init.DualAddressMode = I2C_DUALADDRESS_DISABLE;
  hi2c3.Init.OwnAddress2 = 0;
  hi2c3.Init.GeneralCallMode = I2C_GENERALCALL_DISABLE;
  hi2c3.Init.NoStretchMode = I2C_NOSTRETCH_DISABLE;
  if (HAL_I2C_Init(&hi2c3) != HAL_OK)
  {
    _Error_Handler(__FILE__, __LINE__);
  }

}

/* RNG init function */
static void MX_RNG_Init(void)
{

  hrng.Instance = RNG;
  if (HAL_RNG_Init(&hrng) != HAL_OK)
  {
    _Error_Handler(__FILE__, __LINE__);
  }

}

/* SPI5 init function */
static void MX_SPI5_Init(void)
{

  /* SPI5 parameter configuration*/
  hspi5.Instance = SPI5;
  hspi5.Init.Mode = SPI_MODE_MASTER;
  hspi5.Init.Direction = SPI_DIRECTION_2LINES;
  hspi5.Init.DataSize = SPI_DATASIZE_8BIT;
  hspi5.Init.CLKPolarity = SPI_POLARITY_LOW;
  hspi5.Init.CLKPhase = SPI_PHASE_1EDGE;
  hspi5.Init.NSS = SPI_NSS_SOFT;
  hspi5.Init.BaudRatePrescaler = SPI_BAUDRATEPRESCALER_2;
  hspi5.Init.FirstBit = SPI_FIRSTBIT_MSB;
  hspi5.Init.TIMode = SPI_TIMODE_DISABLE;
  hspi5.Init.CRCCalculation = SPI_CRCCALCULATION_DISABLE;
  hspi5.Init.CRCPolynomial = 10;
  if (HAL_SPI_Init(&hspi5) != HAL_OK)
  {
    _Error_Handler(__FILE__, __LINE__);
  }

}

/* TIM2 init function */
static void MX_TIM2_Init(void)
{

  TIM_MasterConfigTypeDef sMasterConfig;
  TIM_OC_InitTypeDef sConfigOC;

  htim2.Instance = TIM2;
  htim2.Init.Prescaler = 13;
  htim2.Init.CounterMode = TIM_COUNTERMODE_UP;
  htim2.Init.Period = 60000;
  htim2.Init.ClockDivision = TIM_CLOCKDIVISION_DIV1;
  if (HAL_TIM_PWM_Init(&htim2) != HAL_OK)
  {
    _Error_Handler(__FILE__, __LINE__);
  }

  sMasterConfig.MasterOutputTrigger = TIM_TRGO_RESET;
  sMasterConfig.MasterSlaveMode = TIM_MASTERSLAVEMODE_DISABLE;
  if (HAL_TIMEx_MasterConfigSynchronization(&htim2, &sMasterConfig) != HAL_OK)
  {
    _Error_Handler(__FILE__, __LINE__);
  }

  sConfigOC.OCMode = TIM_OCMODE_PWM1;
  sConfigOC.Pulse = 0;
  sConfigOC.OCPolarity = TIM_OCPOLARITY_HIGH;
  sConfigOC.OCFastMode = TIM_OCFAST_DISABLE;
  if (HAL_TIM_PWM_ConfigChannel(&htim2, &sConfigOC, TIM_CHANNEL_1) != HAL_OK)
  {
    _Error_Handler(__FILE__, __LINE__);
  }

  if (HAL_TIM_PWM_ConfigChannel(&htim2, &sConfigOC, TIM_CHANNEL_2) != HAL_OK)
  {
    _Error_Handler(__FILE__, __LINE__);
  }

  HAL_TIM_MspPostInit(&htim2);

}

/* TIM3 init function */
static void MX_TIM3_Init(void)
{

  TIM_MasterConfigTypeDef sMasterConfig;
  TIM_OC_InitTypeDef sConfigOC;

  htim3.Instance = TIM3;
  htim3.Init.Prescaler = 13;
  htim3.Init.CounterMode = TIM_COUNTERMODE_UP;
  htim3.Init.Period = 60000;
  htim3.Init.ClockDivision = TIM_CLOCKDIVISION_DIV1;
  if (HAL_TIM_PWM_Init(&htim3) != HAL_OK)
  {
    _Error_Handler(__FILE__, __LINE__);
  }

  sMasterConfig.MasterOutputTrigger = TIM_TRGO_RESET;
  sMasterConfig.MasterSlaveMode = TIM_MASTERSLAVEMODE_DISABLE;
  if (HAL_TIMEx_MasterConfigSynchronization(&htim3, &sMasterConfig) != HAL_OK)
  {
    _Error_Handler(__FILE__, __LINE__);
  }

  sConfigOC.OCMode = TIM_OCMODE_PWM1;
  sConfigOC.Pulse = 0;
  sConfigOC.OCPolarity = TIM_OCPOLARITY_HIGH;
  sConfigOC.OCFastMode = TIM_OCFAST_DISABLE;
  if (HAL_TIM_PWM_ConfigChannel(&htim3, &sConfigOC, TIM_CHANNEL_1) != HAL_OK)
  {
    _Error_Handler(__FILE__, __LINE__);
  }

  if (HAL_TIM_PWM_ConfigChannel(&htim3, &sConfigOC, TIM_CHANNEL_3) != HAL_OK)
  {
    _Error_Handler(__FILE__, __LINE__);
  }

  HAL_TIM_MspPostInit(&htim3);

}

/* TIM4 init function */
static void MX_TIM4_Init(void)
{

  TIM_MasterConfigTypeDef sMasterConfig;
  TIM_OC_InitTypeDef sConfigOC;

  htim4.Instance = TIM4;
  htim4.Init.Prescaler = 13;
  htim4.Init.CounterMode = TIM_COUNTERMODE_UP;
  htim4.Init.Period = 60000;
  htim4.Init.ClockDivision = TIM_CLOCKDIVISION_DIV1;
  if (HAL_TIM_PWM_Init(&htim4) != HAL_OK)
  {
    _Error_Handler(__FILE__, __LINE__);
  }

  sMasterConfig.MasterOutputTrigger = TIM_TRGO_RESET;
  sMasterConfig.MasterSlaveMode = TIM_MASTERSLAVEMODE_DISABLE;
  if (HAL_TIMEx_MasterConfigSynchronization(&htim4, &sMasterConfig) != HAL_OK)
  {
    _Error_Handler(__FILE__, __LINE__);
  }

  sConfigOC.OCMode = TIM_OCMODE_PWM1;
  sConfigOC.Pulse = 0;
  sConfigOC.OCPolarity = TIM_OCPOLARITY_HIGH;
  sConfigOC.OCFastMode = TIM_OCFAST_DISABLE;
  if (HAL_TIM_PWM_ConfigChannel(&htim4, &sConfigOC, TIM_CHANNEL_2) != HAL_OK)
  {
    _Error_Handler(__FILE__, __LINE__);
  }

  HAL_TIM_MspPostInit(&htim4);

}

/* UART5 init function */
static void MX_UART5_Init(void)
{

  huart5.Instance = UART5;
  huart5.Init.BaudRate = 115200;
  huart5.Init.WordLength = UART_WORDLENGTH_8B;
  huart5.Init.StopBits = UART_STOPBITS_1;
  huart5.Init.Parity = UART_PARITY_NONE;
  huart5.Init.Mode = UART_MODE_TX_RX;
  huart5.Init.HwFlowCtl = UART_HWCONTROL_NONE;
  huart5.Init.OverSampling = UART_OVERSAMPLING_16;
  if (HAL_UART_Init(&huart5) != HAL_OK)
  {
    _Error_Handler(__FILE__, __LINE__);
  }

}

static void MX_DMA_Init(void)
{
  /* DMA controller clock enable */
  __HAL_RCC_DMA2_CLK_ENABLE();

  /* DMA interrupt init */
  /* DMA2_Stream4_IRQn interrupt configuration */
  HAL_NVIC_SetPriority(DMA2_Stream4_IRQn, 0, 0);
  HAL_NVIC_EnableIRQ(DMA2_Stream4_IRQn);

}

/** Configure pins as
        * Analog
        * Input
        * Output
        * EVENT_OUT
        * EXTI
*/
static void MX_GPIO_Init(void)
{

  GPIO_InitTypeDef GPIO_InitStruct;

  /* GPIO Ports Clock Enable */
  __HAL_RCC_GPIOC_CLK_ENABLE();
  __HAL_RCC_GPIOF_CLK_ENABLE();
  __HAL_RCC_GPIOH_CLK_ENABLE();
  __HAL_RCC_GPIOA_CLK_ENABLE();
  __HAL_RCC_GPIOB_CLK_ENABLE();
  __HAL_RCC_GPIOG_CLK_ENABLE();
  __HAL_RCC_GPIOE_CLK_ENABLE();
  __HAL_RCC_GPIOD_CLK_ENABLE();

  /*Configure GPIO pin Output Level */
  HAL_GPIO_WritePin(GPIOC, NCS_MEMS_SPI_Pin|CSX_Pin|OTG_FS_PSO_Pin, GPIO_PIN_RESET);

  /*Configure GPIO pin Output Level */
  HAL_GPIO_WritePin(ACP_RST_GPIO_Port, ACP_RST_Pin, GPIO_PIN_RESET);

  /*Configure GPIO pin Output Level */
  HAL_GPIO_WritePin(GPIOD, RDX_Pin|WRX_DCX_Pin, GPIO_PIN_RESET);

  /*Configure GPIO pin Output Level */
  HAL_GPIO_WritePin(GPIOG, LD3_Pin|LD4_Pin, GPIO_PIN_RESET);

  /*Configure GPIO pins : NCS_MEMS_SPI_Pin CSX_Pin OTG_FS_PSO_Pin */
  GPIO_InitStruct.Pin = NCS_MEMS_SPI_Pin|CSX_Pin|OTG_FS_PSO_Pin;
  GPIO_InitStruct.Mode = GPIO_MODE_OUTPUT_PP;
  GPIO_InitStruct.Pull = GPIO_NOPULL;
  GPIO_InitStruct.Speed = GPIO_SPEED_FREQ_LOW;
  HAL_GPIO_Init(GPIOC, &GPIO_InitStruct);

  /*Configure GPIO pins : B1_Pin MEMS_INT1_Pin MEMS_INT2_Pin TP_INT1_Pin */
  GPIO_InitStruct.Pin = B1_Pin|MEMS_INT1_Pin|MEMS_INT2_Pin|TP_INT1_Pin;
  GPIO_InitStruct.Mode = GPIO_MODE_EVT_RISING;
  GPIO_InitStruct.Pull = GPIO_NOPULL;
  HAL_GPIO_Init(GPIOA, &GPIO_InitStruct);

  /*Configure GPIO pin : ACP_RST_Pin */
  GPIO_InitStruct.Pin = ACP_RST_Pin;
  GPIO_InitStruct.Mode = GPIO_MODE_OUTPUT_PP;
  GPIO_InitStruct.Pull = GPIO_NOPULL;
  GPIO_InitStruct.Speed = GPIO_SPEED_FREQ_LOW;
  HAL_GPIO_Init(ACP_RST_GPIO_Port, &GPIO_InitStruct);

  /*Configure GPIO pin : OTG_FS_OC_Pin */
  GPIO_InitStruct.Pin = OTG_FS_OC_Pin;
  GPIO_InitStruct.Mode = GPIO_MODE_EVT_RISING;
  GPIO_InitStruct.Pull = GPIO_NOPULL;
  HAL_GPIO_Init(OTG_FS_OC_GPIO_Port, &GPIO_InitStruct);

  /*Configure GPIO pin : BOOT1_Pin */
  GPIO_InitStruct.Pin = BOOT1_Pin;
  GPIO_InitStruct.Mode = GPIO_MODE_INPUT;
  GPIO_InitStruct.Pull = GPIO_NOPULL;
  HAL_GPIO_Init(BOOT1_GPIO_Port, &GPIO_InitStruct);

  /*Configure GPIO pin : TE_Pin */
  GPIO_InitStruct.Pin = TE_Pin;
  GPIO_InitStruct.Mode = GPIO_MODE_INPUT;
  GPIO_InitStruct.Pull = GPIO_NOPULL;
  HAL_GPIO_Init(TE_GPIO_Port, &GPIO_InitStruct);

  /*Configure GPIO pins : RDX_Pin WRX_DCX_Pin */
  GPIO_InitStruct.Pin = RDX_Pin|WRX_DCX_Pin;
  GPIO_InitStruct.Mode = GPIO_MODE_OUTPUT_PP;
  GPIO_InitStruct.Pull = GPIO_NOPULL;
  GPIO_InitStruct.Speed = GPIO_SPEED_FREQ_LOW;
  HAL_GPIO_Init(GPIOD, &GPIO_InitStruct);

  /*Configure GPIO pins : LD3_Pin LD4_Pin */
  GPIO_InitStruct.Pin = LD3_Pin|LD4_Pin;
  GPIO_InitStruct.Mode = GPIO_MODE_OUTPUT_PP;
  GPIO_InitStruct.Pull = GPIO_NOPULL;
  GPIO_InitStruct.Speed = GPIO_SPEED_FREQ_LOW;
  HAL_GPIO_Init(GPIOG, &GPIO_InitStruct);

}

/* USER CODE BEGIN 4 */
void saturateFloat(volatile float* i, float min, float max) {
  float val = *i;
  if (val < min) val = min;
  else if (val > max) val = max;
  *i = val;
}

float absfloat(float num){
  if (num < 0) return (num*-1);
  else return num;
}

float deg2rad(float deg){
  float rad = 0;
  rad = (deg * F32_PI) / 180.0;
  return rad;
}

float rad2deg(float rad){
  float deg = 0;
  deg = (rad * 180) / F32_PI;
  return deg;
}

float deg2dc(float angleDeg) {
  float dc = 0;
  dc = (180-angleDeg)/dutyCycle2DegFactor;
  return dc;
}

float dc2deg(float dc) {
  float angleDeg = 0;
  angleDeg = 180 - (dc * dutyCycle2DegFactor);
  return angleDeg;
}

float receivedTurn2dc(uint16_t turnNumber){
  return (turnNumber/20.0 + 2.5);
}

float xRotate2dc(float angleDeg) {
    return (angleDeg/8.0 + 7.5 + servo1calib);
}

float gripRotate2dc(float angleDeg) {
    return (-angleDeg/14.0 + 7.5 + servo4calib);
}

float dc2turnDeg(float dc){
  return ((dc -7.5)*8);
}

float receivedGrip2dc(uint16_t gripValue){
  return (gripValue/16.0 + 5.0);
}

XYCoordinates calculateForwardKinematics(float joint1Angle, float joint2Angle){

  coordinates.X = verLinkLength * cosf(deg2rad(joint1Angle)) + horLinkLength * cosf(deg2rad(joint2Angle));
  coordinates.Y = verLinkLength * sinf(deg2rad(joint1Angle)) - horLinkLength * sinf(deg2rad(joint2Angle));

  return coordinates;
}

XYZCoordinates calculateForwardKinematicsXYZ(float jointRotAngle, float joint1Angle, float joint2Angle){

  coordinatesXYZ.Y = verLinkLength * cosf(deg2rad(joint1Angle)) + horLinkLength * cosf(deg2rad(joint2Angle));
  coordinatesXYZ.Z = verLinkLength * sinf(deg2rad(joint1Angle)) - horLinkLength * sinf(deg2rad(joint2Angle));
  coordinatesXYZ.X = tanf(deg2rad(jointRotAngle))*coordinatesXYZ.Y;

  return coordinatesXYZ;
}

JointAngles calculateInverseKinematics(float xPos, float yPos){

  static volatile float x_temp;
  static volatile float y_temp;
  static float c;
  static float gamma;
  static float alpha;
  static float beta;
  static float epsilon;
  static float delta;
  static float omega;

  x_temp = xPos;
  y_temp = yPos;

  c = sqrtf(xPos*xPos + yPos*yPos); //c^2=a^2+b^2
  gamma = asinf(yPos/c);
  alpha = acosf((verLinkLength*verLinkLength + c*c - horLinkLength*horLinkLength)/(2*verLinkLength*c));

  calculatedAngles.joint1Angle = rad2deg(gamma + alpha);

  beta = acosf((verLinkLength*verLinkLength + horLinkLength*horLinkLength - c*c)/(2*verLinkLength*horLinkLength));
  epsilon = 90 - rad2deg(gamma + alpha);
  delta = 90 - epsilon;
  omega = 180 - delta - rad2deg(beta);

  calculatedAngles.joint2angle = omega;

  return calculatedAngles;
}

JointAngles3Axis calculateInverseKinematics3Axis(float xPos, float yPos, float zPos){

  static volatile float x_temp;
  static volatile float y_temp;
  static float yPosRecalculated;
  static float c;
  static float gamma;
  static float alpha;
  static float beta;
  static float epsilon;
  static float delta;
  static float omega;

  x_temp = xPos;
  y_temp = yPos;

  calculatedAngles3Axis.jointXAngle = rad2deg(atanf(xPos/yPos));

  yPosRecalculated = sqrtf(yPos*yPos + xPos*xPos);

  c = sqrtf(yPosRecalculated*yPosRecalculated + zPos*zPos); //c^2=a^2+b^2
  gamma = asinf(zPos/c);
  alpha = acosf((verLinkLength*verLinkLength + c*c - horLinkLength*horLinkLength)/(2*verLinkLength*c));

  calculatedAngles3Axis.jointZAngle = rad2deg(gamma + alpha);

  beta = acosf((verLinkLength*verLinkLength + horLinkLength*horLinkLength - c*c)/(2*verLinkLength*horLinkLength));
  epsilon = 90 - rad2deg(gamma + alpha);
  delta = 90 - epsilon;
  omega = 180 - delta - rad2deg(beta);

  calculatedAngles3Axis.jointYAngle = omega;

  return calculatedAngles3Axis;
}

float convertADCtomm(uint32_t in){
  return in/500.0;
}

/**
   * @brief Count characters in char array
	 * @param ptr: pointer to char array
   * @retval Number of characters in array
   */
uint16_t SizeofCharArray(char *ptr)
{
  /* Local variables */
  uint16_t len = 0;

  /* Search until end char */
  while (ptr[len] != '\0') {
    len++;
  }
  return len;
}
/* USER CODE END 4 */

/* StartDefaultTask function */
void StartDefaultTask(void const * argument)
{
  /* init code for USB_DEVICE */
  MX_USB_DEVICE_Init();

/* Graphic application */
  GRAPHICS_MainTask();

  /* USER CODE BEGIN 5 */

  /* Infinite loop */
  for(;;)
  {
    osDelay(500);
    taskCounterDefaultTask++;
  }
  /* USER CODE END 5 */
}

/* StartCommTask function */
void StartCommTask(void const * argument)
{
  /* USER CODE BEGIN StartCommTask */
  uint16_t Len = 0;
  //strcpy(txBuf, "echo: ");

  int16_t xAxisValue = 0;
  int16_t yAxisValue = 100;
  int16_t zAxisValue = 100;

  float xAxisCm = 0;
  float yAxisCm = 0;
  float zAxisCm = 0;

  JointAngles3Axis finalJointAngles3Axis;

  //uint16_t servo1ComPosRef = 75;
  /* Infinite loop */
  for(;;)
  {
    BSP_LED_Toggle(LED3);
    if (receiveState == 1){
      if ((rxBuf[0] == 'P') && (rxBuf[4] == ';') && (rxBuf[8] == ';') && (rxBuf[12] == '\r')){//&& (rxBuf[12] == ';') && (rxBuf[16] == '\r')){
        xAxisValue = (int16_t)((rxBuf[1]  - '0')*100 + (rxBuf[2]  - '0')*10 + (rxBuf[3]  - '0')*1);
        yAxisValue = (int16_t)((rxBuf[5]  - '0')*100 + (rxBuf[6]  - '0')*10 + (rxBuf[7]  - '0')*1);
        zAxisValue = (int16_t)((rxBuf[9]  - '0')*100 + (rxBuf[10]  - '0')*10 + (rxBuf[11]  - '0')*1);
        //aAxisValue = (int16_t)((rxBuf[13]  - '0')*100 + (rxBuf[14]  - '0')*10 + (rxBuf[15]  - '0')*1);

        xAxisCm = ((float)xAxisValue-100)/10.0;
        yAxisCm = ((float)yAxisValue)/10.0;
        zAxisCm = ((float)zAxisValue-50)/10.0;

        if (cycleRepeat == 0){
          finalJointAngles3Axis = calculateInverseKinematics3Axis(xAxisCm/100.0,yAxisCm/100.0,zAxisCm/100.0);
          servo3NewPosRef = deg2dc(finalJointAngles3Axis.jointZAngle);
          servo2NewPosRef = deg2dc(finalJointAngles3Axis.jointYAngle);
          servo1NewPosRef = xRotate2dc(finalJointAngles3Axis.jointXAngle);
          servo4NewPosRef = gripRotate2dc(finalJointAngles3Axis.jointXAngle);

          if ((absfloat(servo3NewPosRef-servo3CurrPos) > absfloat(servo2NewPosRef-servo2CurrPos)) && (absfloat(servo3NewPosRef-servo3CurrPos) > absfloat(servo1NewPosRef-servo1CurrPos))){
            servo3StepSize = targetStepSizeVar;
            numberOfSteps = absfloat(servo3NewPosRef-servo3CurrPos)/targetStepSizeVar;
            servo2StepSize = absfloat(servo2NewPosRef-servo2CurrPos)/numberOfSteps;
            servo1StepSize = absfloat(servo1NewPosRef-servo1CurrPos)/numberOfSteps;
            servo4StepSize = absfloat(servo4NewPosRef-servo4CurrPos)/numberOfSteps;
          }
          else if ((absfloat(servo2NewPosRef-servo2CurrPos) > absfloat(servo3NewPosRef-servo3CurrPos)) && (absfloat(servo2NewPosRef-servo2CurrPos) > absfloat(servo1NewPosRef-servo1CurrPos))){
            servo2StepSize = targetStepSizeVar;
            numberOfSteps = absfloat(servo2NewPosRef-servo2CurrPos)/targetStepSizeVar;
            servo3StepSize = absfloat(servo3NewPosRef-servo3CurrPos)/numberOfSteps;
            servo1StepSize = absfloat(servo1NewPosRef-servo1CurrPos)/numberOfSteps;
            servo4StepSize = absfloat(servo4NewPosRef-servo4CurrPos)/numberOfSteps;
          }
          else{
            servo1StepSize = targetStepSizeVar;
            numberOfSteps = absfloat(servo1NewPosRef-servo1CurrPos)/targetStepSizeVar;
            servo3StepSize = absfloat(servo3NewPosRef-servo3CurrPos)/numberOfSteps;
            servo2StepSize = absfloat(servo2NewPosRef-servo2CurrPos)/numberOfSteps;
            servo4StepSize = absfloat(servo4NewPosRef-servo4CurrPos)/numberOfSteps;
          }
        }
        sprintf(txBuf, "OK: %s\r", rxBuf);
        Len = SizeofCharArray((char*)txBuf);
        CDC_Transmit_HS((uint8_t*)txBuf, Len);
      }
      else if ((rxBuf[0] == 'P') && (rxBuf[1] == 'E') && (rxBuf[2] == 'N') && (rxBuf[4] == '\r')){
        PenControlActive = (int16_t)(rxBuf[3]  - '0');
        sprintf(txBuf, "OK: %s\r", rxBuf);
        Len = SizeofCharArray((char*)txBuf);
        CDC_Transmit_HS((uint8_t*)txBuf, Len);
      }
      else if ((rxBuf[0] == 'D') && (rxBuf[1] == 'Y') && (rxBuf[2] == 'N') && (rxBuf[4] == '\r')){
        targetStepSizeVar = (int16_t)(rxBuf[3]  - '0') * 0.01;
        sprintf(txBuf, "OK: %s\r", rxBuf);
        Len = SizeofCharArray((char*)txBuf);
        CDC_Transmit_HS((uint8_t*)txBuf, Len);
      }
      else{
        sprintf(txBuf, "ERR: %s\r", rxBuf);
        Len = SizeofCharArray((char*)txBuf);
        CDC_Transmit_HS((uint8_t*)txBuf, Len);

      }

      receiveState = 0;

    }
    osDelay(1000);
    taskCounterCommTask++;
  }
  /* USER CODE END StartCommTask */
}

/* StartSensorTask function */
void StartSensorTask(void const * argument)
{
  /* USER CODE BEGIN StartSensorTask */
  HAL_ADC_Start_DMA(&hadc1, (uint32_t*)ADC_Buf,3);
  /* Infinite loop */
  for(;;)
  {
    pressLength = convertADCtomm(val[0]);
    osDelay(10);
    taskCounterSensorTask++;
  }
  /* USER CODE END StartSensorTask */
}

/* StartControlTask function */
void StartControlTask(void const * argument)
{
  /* USER CODE BEGIN StartControlTask */
  /* Infinite loop */
  for(;;)
  {

    saturateFloat(&servo1NewPosRef, servo1Min, servo1Max);
    saturateFloat(&servo2NewPosRef, servo2Min, servo2Max);
    saturateFloat(&servo3NewPosRef, servo3Min, servo3Max);
    saturateFloat(&servo4NewPosRef, servo4Min, servo4Max);
    saturateFloat(&servo5NewPosRef, servo5Min, servo5Max);

    if (servo1NewPosRef > servo1CurrPos){
      if (servo1NewPosRef > servo1CurrPos + servo1StepSize){
        servo1NewPos = servo1CurrPos + servo1StepSize;
      }
      else{
        servo1NewPos = servo1NewPosRef;
      }
    }
    else if (servo1NewPosRef < servo1CurrPos){
      if (servo1NewPosRef < servo1CurrPos - servo1StepSize){
        servo1NewPos = servo1CurrPos - servo1StepSize;
      }
      else{
        servo1NewPos = servo1NewPosRef;
      }
    }

    if (servo2NewPosRef > servo2CurrPos){
      if (servo2NewPosRef > servo2CurrPos + servo2StepSize){
        servo2NewPos = servo2CurrPos + servo2StepSize;
      }
      else{
        servo2NewPos = servo2NewPosRef;
      }
    }
    else if (servo2NewPosRef < servo2CurrPos){
      if (servo2NewPosRef < servo2CurrPos - servo2StepSize){
        servo2NewPos = servo2CurrPos - servo2StepSize;
      }
      else{
        servo2NewPos = servo2NewPosRef;
      }
    }

    if (servo3NewPosRef > servo3CurrPos){
      if (servo3NewPosRef > servo3CurrPos + servo3StepSize){
        servo3NewPos = servo3CurrPos + servo3StepSize;
      }
      else{
        servo3NewPos = servo3NewPosRef;
      }
    }
    else if (servo3NewPosRef < servo3CurrPos){
      if (servo3NewPosRef < servo3CurrPos - servo3StepSize){
        servo3NewPos = servo3CurrPos - servo3StepSize;
      }
      else{
        servo3NewPos = servo3NewPosRef;
      }
    }

    if (servo4NewPosRef > servo4CurrPos){
      if (servo4NewPosRef > servo4CurrPos + servo4StepSize){
        servo4NewPos = servo4CurrPos + servo4StepSize;
      }
      else{
        servo4NewPos = servo4NewPosRef;
      }
    }
    else if (servo4NewPosRef < servo4CurrPos){
      if (servo4NewPosRef < servo4CurrPos - servo4StepSize){
        servo4NewPos = servo4CurrPos - servo4StepSize;
      }
      else{
        servo4NewPos = servo4NewPosRef;
      }
    }

    if (servo5NewPosRef > servo5CurrPos){
      if (servo5NewPosRef > servo5CurrPos + servo5StepSize){
        servo5NewPos = servo5CurrPos + servo5StepSize;
      }
      else{
        servo5NewPos = servo5NewPosRef;
      }
    }
    else if (servo5NewPosRef < servo5CurrPos){
      if (servo5NewPosRef < servo5CurrPos - servo5StepSize){
        servo5NewPos = servo5CurrPos - servo5StepSize;
      }
      else{
        servo5NewPos = servo5NewPosRef;
      }
    }

    if (PenControlActive == 1){
      if ((pressLength - pressTarget) < -pressThreshold){
        servo3NewPos = servo3CurrPos+0.02;
        saturateFloat(&servo3NewPos, servo3Min, servo3Max);
      }
      else if ((pressLength - pressTarget) > pressThreshold){
        servo3NewPos = servo3CurrPos-0.02;
        saturateFloat(&servo3NewPos, servo3Min, servo3Max);
      }
      else {
        servo3NewPos = servo3CurrPos;
      }
      if ((servo3NewPos == servo3Min) || (servo3NewPos == servo3Max)){
        PenControlActive = 0;
      }
    }

    TIM2->CCR1 = (int)(servo1NewPos*60000*2/100);//7.5 = 1.5ms
    TIM2->CCR2 = (int)(servo2NewPos*60000*2/100);//10 = 2ms
    TIM3->CCR1 = (int)(servo3NewPos*60000*2/100);//5 = 1ms
    TIM3->CCR3 = (int)(servo4NewPos*60000*2/100);
    TIM4->CCR2 = (int)(servo5NewPos*60000*2/100);

    servo1CurrPos = servo1NewPos;
    servo2CurrPos = servo2NewPos;
    servo3CurrPos = servo3NewPos;
    servo4CurrPos = servo4NewPos;
    servo5CurrPos = servo5NewPos;

    osDelay(10);
    taskCounterControlTask++;
  }
  /* USER CODE END StartControlTask */
}

/* StartServoRampTask function */
void StartServoRampTask(void const * argument)
{
  /* USER CODE BEGIN StartServoRampTask */
  int taskCounter = 0;
  int taskDelay = 1000;
  /* Infinite loop */
  for(;;)
  {
    if (mode % 2 == 1) {
      if (taskCounter % 2 == 0){
        servo2NewPosRef = 8;
        servo3NewPosRef = 6.8;
      }
      else{
        servo2NewPosRef = 10;
        servo3NewPosRef = 6.8;
      }
      taskCounter++;
      osDelay(500);
    }
    else if (cycleRepeat == 1){
      if (taskCounter % 12 == 0){
        servo3NewPosRef = 6.8;
        servo4NewPosRef = 6;
        servo1StepSize = 0.03;
        taskDelay = 1000;
      }
      else if (taskCounter % 12 == 1){
        servo2NewPosRef = 9;
        taskDelay = 1000;
      }
      else if (taskCounter % 12 == 2){
        servo1NewPosRef = 7.5;
        taskDelay = 2000;
      }
      else if (taskCounter % 12 == 3){
        servo1NewPosRef = 3;
        servo2NewPosRef = 7.5;
        taskDelay = 2000;
      }
      else if (taskCounter % 12 == 4){

        servo3NewPosRef = 9.25;
        taskDelay = 1500;
      }
      else if (taskCounter % 12 == 5){
        servo4NewPosRef = 9.2;
        taskDelay = 1500;
      }
      else if (taskCounter % 12 == 6){
        servo1NewPosRef = 7.5;
        servo2NewPosRef = 10.7;
        servo3NewPosRef = 6.8;
        servo2StepSize = 0.03;
        servo3StepSize = 0.03;
        taskDelay = 2500;
      }
      else if (taskCounter % 12 == 7){
        servo2NewPosRef = 10.7;
        servo3NewPosRef = 8;
        servo2StepSize = 0.03;
        taskDelay = 500;
      }
      else if (taskCounter % 12 == 8){
        servo2NewPosRef = 10.7;
        servo3NewPosRef = 6.8;
        taskDelay = 1000;
      }
      else if (taskCounter % 12 == 9){
        servo1NewPosRef = 3;
        servo2NewPosRef = 7.5;
        servo2StepSize = 0.03;
        taskDelay = 2000;
      }
      else if (taskCounter % 12 == 10){
        servo3NewPosRef = 9.25;
        taskDelay = 1500;
      }
      else if (taskCounter % 12 == 11){
        servo2StepSize = 0.03;
        servo4NewPosRef = 6;
        taskDelay = 1500;
        taskDelay = 30000;
        //cycleRepeat = 0;
      }

      taskCounter++;
      osDelay(taskDelay);
      taskCounterServoRampTask++;
    }
    else{
      osDelay(500);
      taskCounterServoRampTask++;
    }
  }
  /* USER CODE END StartServoRampTask */
}

/* StartTsTask function */
void StartTsTask(void const * argument)
{
  /* USER CODE BEGIN StartTsTask */
  TS_StateTypeDef  State;

  /* Infinite loop */
  for(;;)
  {
    BSP_TS_GetState(&State);

    TSx = State.X;
    TSy = State.Y;

    if (State.TouchDetected){
      BSP_LCD_SetTextColor(LCD_COLOR_GREEN);
      BSP_LCD_DrawCircle(TSx,TSy,3);
      BSP_LCD_SetTextColor(BACKGROUND_COLOR);
      //BSP_LCD_FillCircle(120, 160, 80);
    }
    else{
      //BSP_LCD_SetTextColor(LCD_COLOR_RED);
      //BSP_LCD_FillCircle(120, 160, 80);
    }

    osDelay(100);
    taskCounterTsTask++;
  }
  /* USER CODE END StartTsTask */
}

/* StartOldGraphicsTask function */
void StartOldGraphicsTask(void const * argument)
{
  /* USER CODE BEGIN StartOldGraphicsTask */
  int elapsedTime = 0;
  char textBuf[30];
  float verLinkAngleAfterRefresh = 0;
  float horLinkAngleAfterRefresh = 0;
  float turnAngleAfterRefresh = 0;

  XYZCoordinates endPoint;
  //JointAngles finalJointAngles;
  osDelay(1000);

  BSP_LCD_SelectLayer(0);

  BSP_LCD_Clear(LCD_COLOR_BLACK);
  BSP_LCD_SetBackColor(LCD_COLOR_BLACK);
  BSP_LCD_SetTextColor(LCD_COLOR_CYAN);
  BSP_LCD_SetFont(&Font16);
  BSP_LCD_DrawRect(0,0,239,319);
  BSP_LCD_DisplayStringAt(5,8,"RobotArm Control 2.0",LEFT_MODE);
  BSP_LCD_SetTextColor(LCD_COLOR_ORANGE);

  /* Infinite loop */
  for(;;)
  {
    if ((BSP_PB_GetState(BUTTON_KEY) == SET) && (elapsedTime > 10)){
      //mode++;
      //cycleRepeat = 1;
      cycleRepeat ^= 1;
      BSP_LCD_DisplayChar(5,25,(char)(cycleRepeat+48));
      elapsedTime = 0;
    }

    if (elapsedTime < 100){
      elapsedTime+=1;
    }

    verLinkAngle = dc2deg(servo3CurrPos);
    horLinkAngle = dc2deg(servo2CurrPos);
    turnAngle    = dc2turnDeg(servo1CurrPos - servo1calib);

    //sprintf(textBuf, "V joint: %.2f deg",  verLinkAngle);
    //BSP_LCD_DisplayStringAt(5, 45, (unsigned char*) textBuf, LEFT_MODE);
    //sprintf(textBuf, "H joint: %.2f deg",  horLinkAngle);
    //BSP_LCD_DisplayStringAt(5, 60, (unsigned char*) textBuf, LEFT_MODE);

    endPoint = calculateForwardKinematicsXYZ(turnAngle,verLinkAngle,horLinkAngle);

    BSP_LCD_SetTextColor(LCD_COLOR_ORANGE);
    sprintf(textBuf, "X: %.1f cm    ", (endPoint.X*100));
    BSP_LCD_DisplayStringAt(5, 45, (unsigned char*) textBuf, LEFT_MODE);
    sprintf(textBuf, "Y: %.1f cm    ", (endPoint.Y*100));
    BSP_LCD_DisplayStringAt(5, 60, (unsigned char*) textBuf, LEFT_MODE);
    sprintf(textBuf, "Z: %.1f cm    ", (endPoint.Z*100));
    BSP_LCD_DisplayStringAt(5, 75, (unsigned char*) textBuf, LEFT_MODE);
    sprintf(textBuf, "A: %.1f mm    ", (pressLength));
    BSP_LCD_DisplayStringAt(5, 90, (unsigned char*) textBuf, LEFT_MODE);

    if (((verLinkAngleAfterRefresh != verLinkAngle) || (horLinkAngleAfterRefresh != horLinkAngle) || (turnAngleAfterRefresh != turnAngle)) && (graphicsEna)) {
      BSP_LCD_SetTextColor(LCD_COLOR_BLACK);
      BSP_LCD_FillRect(5,135,230,180);
      BSP_LCD_SetTextColor(LCD_COLOR_ORANGE);

      verLinkAngleAfterRefresh = verLinkAngle;
      horLinkAngleAfterRefresh = horLinkAngle;
      turnAngleAfterRefresh    = turnAngle;

      verLinkPoints[0].X = 45;
      verLinkPoints[0].Y = 250;
      verLinkPoints[1].X = verLinkPoints[0].X + 10;
      verLinkPoints[1].Y = verLinkPoints[0].Y;

      verLinkPoints[3].X = (int16_t)(verLinkPoints[0].X + (74.25*cosf(deg2rad(verLinkAngle))));
      verLinkPoints[3].Y = (int16_t)(verLinkPoints[0].Y - (74.25*sinf(deg2rad(verLinkAngle))));
      verLinkPoints[2].X = verLinkPoints[3].X + 10;
      verLinkPoints[2].Y = verLinkPoints[3].Y;

      horLinkPoints[0].X = verLinkPoints[2].X;
      horLinkPoints[0].Y = verLinkPoints[2].Y;
      horLinkPoints[1].X = verLinkPoints[2].X;
      horLinkPoints[1].Y = verLinkPoints[2].Y + 10;

      horLinkPoints[3].X = (int16_t)(horLinkPoints[0].X + (82.5*cosf(deg2rad(horLinkAngle))));
      horLinkPoints[3].Y = (int16_t)(horLinkPoints[0].Y + (82.5*sinf(deg2rad(horLinkAngle))));
      horLinkPoints[2].X = horLinkPoints[3].X;
      horLinkPoints[2].Y = horLinkPoints[3].Y + 10;

      BSP_LCD_FillRect(30, 250, 40, 40);
      BSP_LCD_FillPolygon(verLinkPoints, 4);
      BSP_LCD_FillPolygon(horLinkPoints, 4);
      BSP_LCD_FillRect(horLinkPoints[3].X, horLinkPoints[3].Y, 30, 10);

      BSP_LCD_FillCircle(50,250,10);
      BSP_LCD_FillCircle(verLinkPoints[3].X+5,verLinkPoints[3].Y+5,10);
      BSP_LCD_FillCircle(horLinkPoints[3].X,horLinkPoints[3].Y+5,10);
      BSP_LCD_SetTextColor(LCD_COLOR_BLACK);
      BSP_LCD_FillCircle(50,250,5);
      BSP_LCD_FillCircle(verLinkPoints[3].X+5,verLinkPoints[3].Y+5,5);
      BSP_LCD_FillCircle(horLinkPoints[3].X,horLinkPoints[3].Y+5,5);
      BSP_LCD_SetTextColor(LCD_COLOR_ORANGE);

      if (turnAngle < -0.1){
        sprintf(textBuf, "   %.1f ->",  (turnAngle*-1));
      }
      else if (turnAngle > 0.1){
        sprintf(textBuf, "<- %.1f",  turnAngle);
      }
      else {
        sprintf(textBuf, "   %.1f",  turnAngle);
      }
      BSP_LCD_SetFont(&Font12);
      BSP_LCD_DisplayStringAt(15, 300, (unsigned char*) textBuf, LEFT_MODE);
      BSP_LCD_SetFont(&Font16);
    }

    osDelay(100);
    taskCounterOldGraphicsTask++;
  }
  /* USER CODE END StartOldGraphicsTask */
}

void HAL_TIM_PeriodElapsedCallback(TIM_HandleTypeDef *htim)
{
  if (htim->Instance == TIM6) {
    HAL_IncTick();
  }
}

void _Error_Handler(char *file, int line)
{
  while(1)
  {
  }
}

/************************ (C) COPYRIGHT STMicroelectronics *****END OF FILE****/
